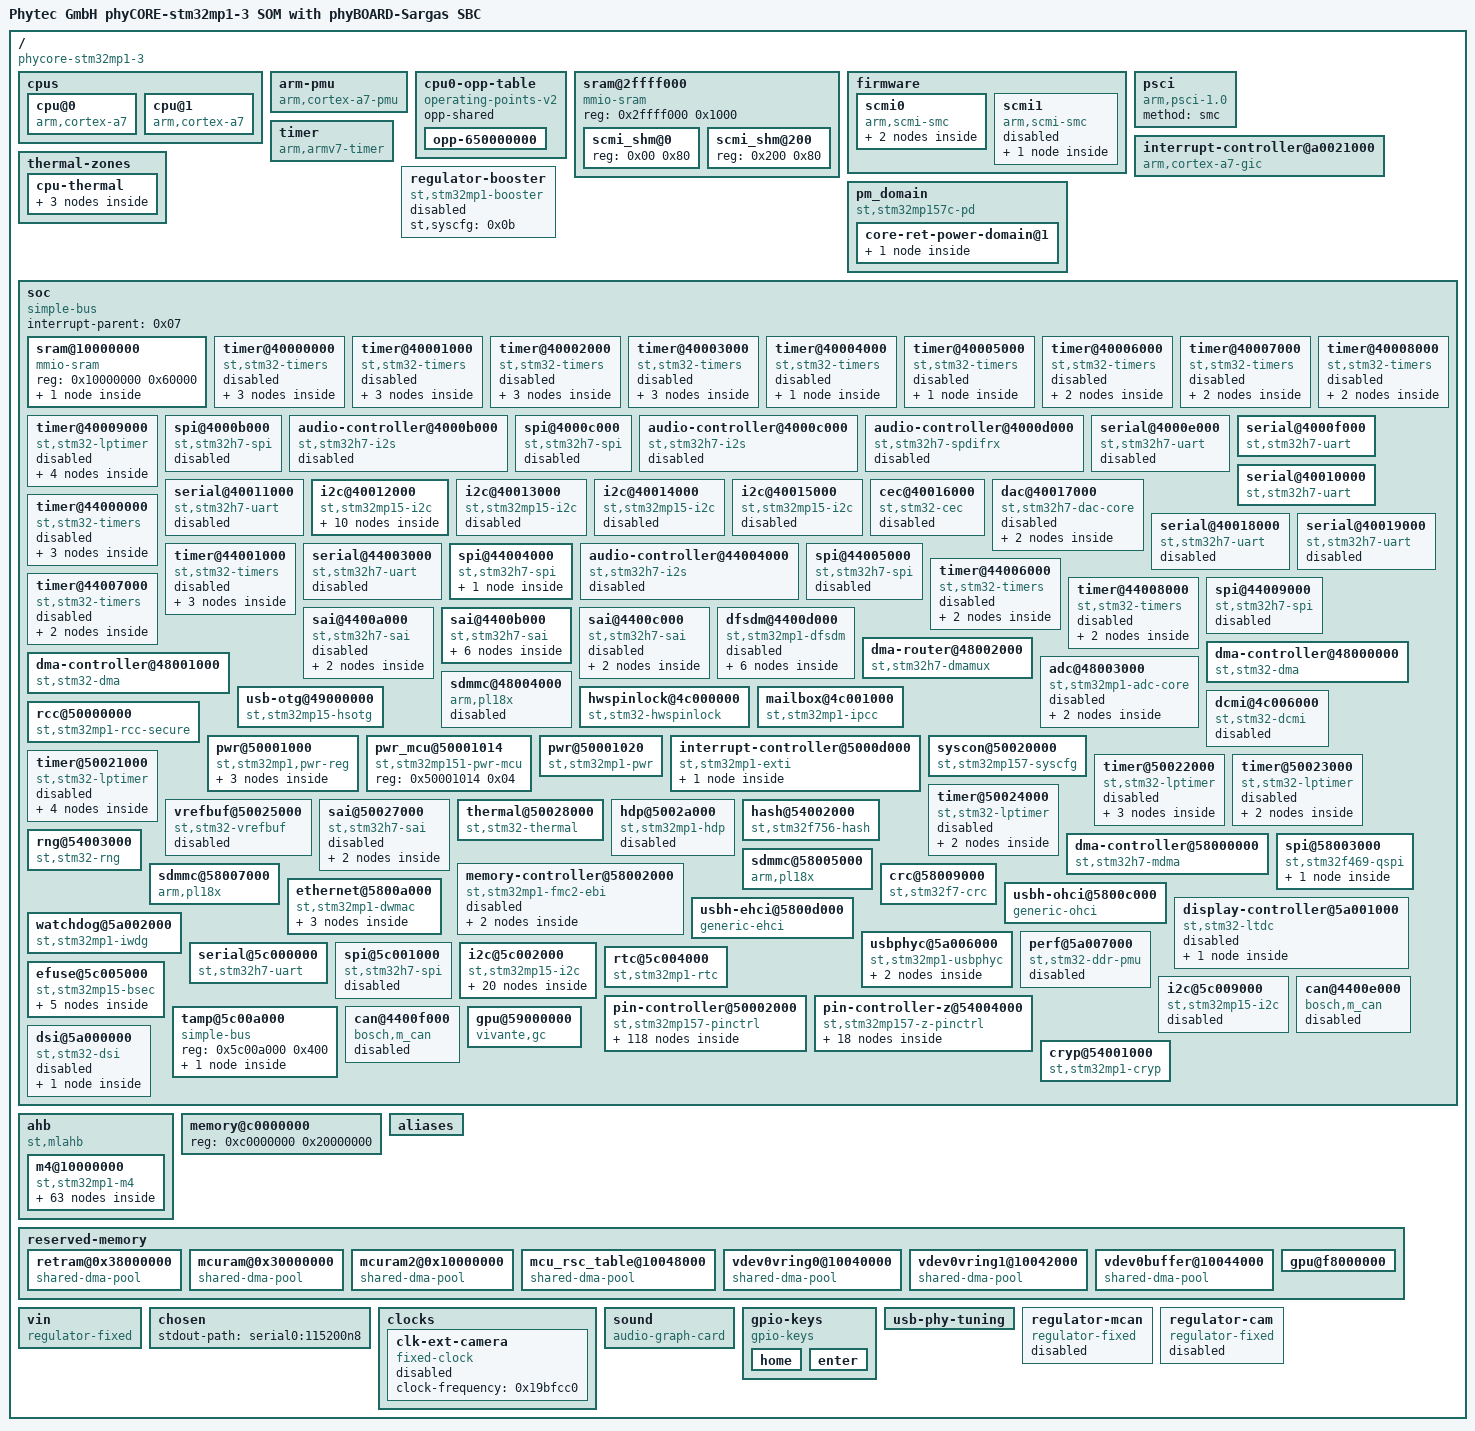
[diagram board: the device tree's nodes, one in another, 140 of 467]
/dts-v1/;

/ {
	#address-cells = <0x01>;
	#size-cells = <0x01>;
	model = "Phytec GmbH phyCORE-stm32mp1-3 SOM with phyBOARD-Sargas SBC";
	compatible = "phycore-stm32mp1-3\0phytec,stm32mp1-pcm068\0phytec,stm32mp1-pcm939\0st,stm32mp157";

	cpus {
		#address-cells = <0x01>;
		#size-cells = <0x00>;

		cpu@0 {
			compatible = "arm,cortex-a7";
			device_type = "cpu";
			reg = <0x00>;
			clocks = <0x01 0x07>;
			clock-names = "cpu";
			operating-points-v2 = <0x02>;
			nvmem-cells = <0x03>;
			nvmem-cell-names = "part_number";
			#cooling-cells = <0x02>;
			cpu-supply = <0x04>;
			phandle = <0x05>;
		};

		cpu@1 {
			compatible = "arm,cortex-a7";
			device_type = "cpu";
			reg = <0x01>;
			clocks = <0x01 0x07>;
			clock-names = "cpu";
			operating-points-v2 = <0x02>;
			cpu-supply = <0x04>;
			phandle = <0x06>;
		};
	};

	arm-pmu {
		compatible = "arm,cortex-a7-pmu";
		interrupts = <0x00 0xc8 0x04 0x00 0xc9 0x04>;
		interrupt-affinity = <0x05 0x06>;
		interrupt-parent = <0x07>;
	};

	cpu0-opp-table {
		compatible = "operating-points-v2";
		opp-shared;
		phandle = <0x02>;

		opp-650000000 {
			opp-hz = <0x00 0x26be3680>;
			opp-microvolt = <0x124f80>;
			opp-supported-hw = <0x01>;
		};
	};

	sram@2ffff000 {
		compatible = "mmio-sram";
		reg = <0x2ffff000 0x1000>;
		#address-cells = <0x01>;
		#size-cells = <0x01>;
		ranges = <0x00 0x2ffff000 0x1000>;
		phandle = <0x72>;

		scmi_shm@0 {
			reg = <0x00 0x80>;
			phandle = <0x08>;
		};

		scmi_shm@200 {
			reg = <0x200 0x80>;
			phandle = <0x09>;
		};
	};

	firmware {

		scmi0 {
			compatible = "arm,scmi-smc";
			#address-cells = <0x01>;
			#size-cells = <0x00>;
			arm,smc-id = <0x82002000>;
			shmem = <0x08>;
			phandle = <0x73>;

			protocol@14 {
				reg = <0x14>;
				#clock-cells = <0x01>;
				phandle = <0x01>;
			};

			protocol@16 {
				reg = <0x16>;
				#reset-cells = <0x01>;
				phandle = <0x38>;
			};
		};

		scmi1 {
			compatible = "arm,scmi-smc";
			#address-cells = <0x01>;
			#size-cells = <0x00>;
			arm,smc-id = <0x82002001>;
			shmem = <0x09>;
			status = "disabled";
			phandle = <0x74>;

			protocol@14 {
				reg = <0x14>;
				#clock-cells = <0x01>;
				phandle = <0x75>;
			};
		};
	};

	psci {
		compatible = "arm,psci-1.0";
		method = "smc";
	};

	interrupt-controller@a0021000 {
		compatible = "arm,cortex-a7-gic";
		#interrupt-cells = <0x03>;
		interrupt-controller;
		reg = <0xa0021000 0x1000 0xa0022000 0x2000>;
		phandle = <0x07>;
	};

	timer {
		compatible = "arm,armv7-timer";
		interrupts = <0x01 0x0d 0xf08 0x01 0x0e 0xf08 0x01 0x0b 0xf08 0x01 0x0a 0xf08>;
		interrupt-parent = <0x07>;
		always-on;
	};

	thermal-zones {

		cpu-thermal {
			polling-delay-passive = <0x00>;
			polling-delay = <0x00>;
			thermal-sensors = <0x0a>;
			phandle = <0x76>;

			trips {

				cpu-crit {
					temperature = <0x1d4c0>;
					hysteresis = <0x00>;
					type = "critical";
				};
			};

			cooling-maps {
			};
		};
	};

	regulator-booster {
		compatible = "st,stm32mp1-booster";
		st,syscfg = <0x0b>;
		status = "disabled";
		phandle = <0x77>;
	};

	pm_domain {
		#address-cells = <0x01>;
		#size-cells = <0x00>;
		compatible = "st,stm32mp157c-pd";

		core-ret-power-domain@1 {
			#address-cells = <0x01>;
			#size-cells = <0x00>;
			reg = <0x01>;
			#power-domain-cells = <0x00>;
			label = "CORE-RETENTION";
			phandle = <0x78>;

			core-power-domain@2 {
				reg = <0x02>;
				#power-domain-cells = <0x00>;
				label = "CORE";
				phandle = <0x0f>;
			};
		};
	};

	soc {
		compatible = "simple-bus";
		#address-cells = <0x01>;
		#size-cells = <0x01>;
		interrupt-parent = <0x07>;
		ranges;

		sram@10000000 {
			compatible = "mmio-sram";
			reg = <0x10000000 0x60000>;
			#address-cells = <0x01>;
			#size-cells = <0x01>;
			ranges = <0x00 0x10000000 0x60000>;
			phandle = <0x79>;

			dma_pool@0 {
				reg = <0x50000 0x10000>;
				pool;
				phandle = <0x28>;
			};
		};

		timer@40000000 {
			#address-cells = <0x01>;
			#size-cells = <0x00>;
			compatible = "st,stm32-timers";
			reg = <0x40000000 0x400>;
			clocks = <0x0c 0xc5>;
			clock-names = "int";
			dmas = <0x0d 0x12 0x400 0x80000001 0x0d 0x13 0x400 0x80000001 0x0d 0x14 0x400 0x80000001 0x0d 0x15 0x400 0x80000001 0x0d 0x16 0x400 0x80000001>;
			dma-names = "ch1\0ch2\0ch3\0ch4\0up";
			status = "disabled";
			phandle = <0x7a>;

			pwm {
				compatible = "st,stm32-pwm";
				#pwm-cells = <0x03>;
				status = "disabled";
			};

			timer@1 {
				compatible = "st,stm32h7-timer-trigger";
				reg = <0x01>;
				status = "disabled";
			};

			counter {
				compatible = "st,stm32-timer-counter";
				status = "disabled";
			};
		};

		timer@40001000 {
			#address-cells = <0x01>;
			#size-cells = <0x00>;
			compatible = "st,stm32-timers";
			reg = <0x40001000 0x400>;
			clocks = <0x0c 0xc6>;
			clock-names = "int";
			dmas = <0x0d 0x17 0x400 0x80000001 0x0d 0x18 0x400 0x80000001 0x0d 0x19 0x400 0x80000001 0x0d 0x1a 0x400 0x80000001 0x0d 0x1b 0x400 0x80000001 0x0d 0x1c 0x400 0x80000001>;
			dma-names = "ch1\0ch2\0ch3\0ch4\0up\0trig";
			status = "disabled";
			phandle = <0x7b>;

			pwm {
				compatible = "st,stm32-pwm";
				#pwm-cells = <0x03>;
				status = "disabled";
			};

			timer@2 {
				compatible = "st,stm32h7-timer-trigger";
				reg = <0x02>;
				status = "disabled";
			};

			counter {
				compatible = "st,stm32-timer-counter";
				status = "disabled";
			};
		};

		timer@40002000 {
			#address-cells = <0x01>;
			#size-cells = <0x00>;
			compatible = "st,stm32-timers";
			reg = <0x40002000 0x400>;
			clocks = <0x0c 0xc7>;
			clock-names = "int";
			dmas = <0x0d 0x1d 0x400 0x80000001 0x0d 0x1e 0x400 0x80000001 0x0d 0x1f 0x400 0x80000001 0x0d 0x20 0x400 0x80000001>;
			dma-names = "ch1\0ch2\0ch3\0ch4";
			status = "disabled";
			phandle = <0x7c>;

			pwm {
				compatible = "st,stm32-pwm";
				#pwm-cells = <0x03>;
				status = "disabled";
			};

			timer@3 {
				compatible = "st,stm32h7-timer-trigger";
				reg = <0x03>;
				status = "disabled";
			};

			counter {
				compatible = "st,stm32-timer-counter";
				status = "disabled";
			};
		};

		timer@40003000 {
			#address-cells = <0x01>;
			#size-cells = <0x00>;
			compatible = "st,stm32-timers";
			reg = <0x40003000 0x400>;
			clocks = <0x0c 0xc8>;
			clock-names = "int";
			dmas = <0x0d 0x37 0x400 0x80000001 0x0d 0x38 0x400 0x80000001 0x0d 0x39 0x400 0x80000001 0x0d 0x3a 0x400 0x80000001 0x0d 0x3b 0x400 0x80000001 0x0d 0x3c 0x400 0x80000001>;
			dma-names = "ch1\0ch2\0ch3\0ch4\0up\0trig";
			status = "disabled";
			phandle = <0x7d>;

			pwm {
				compatible = "st,stm32-pwm";
				#pwm-cells = <0x03>;
				status = "disabled";
			};

			timer@4 {
				compatible = "st,stm32h7-timer-trigger";
				reg = <0x04>;
				status = "disabled";
			};

			counter {
				compatible = "st,stm32-timer-counter";
				status = "disabled";
			};
		};

		timer@40004000 {
			#address-cells = <0x01>;
			#size-cells = <0x00>;
			compatible = "st,stm32-timers";
			reg = <0x40004000 0x400>;
			clocks = <0x0c 0xc9>;
			clock-names = "int";
			dmas = <0x0d 0x45 0x400 0x80000001>;
			dma-names = "up";
			status = "disabled";
			phandle = <0x7e>;

			timer@5 {
				compatible = "st,stm32h7-timer-trigger";
				reg = <0x05>;
				status = "disabled";
			};
		};

		timer@40005000 {
			#address-cells = <0x01>;
			#size-cells = <0x00>;
			compatible = "st,stm32-timers";
			reg = <0x40005000 0x400>;
			clocks = <0x0c 0xca>;
			clock-names = "int";
			dmas = <0x0d 0x46 0x400 0x80000001>;
			dma-names = "up";
			status = "disabled";
			phandle = <0x7f>;

			timer@6 {
				compatible = "st,stm32h7-timer-trigger";
				reg = <0x06>;
				status = "disabled";
			};
		};

		timer@40006000 {
			#address-cells = <0x01>;
			#size-cells = <0x00>;
			compatible = "st,stm32-timers";
			reg = <0x40006000 0x400>;
			clocks = <0x0c 0xcb>;
			clock-names = "int";
			status = "disabled";
			phandle = <0x80>;

			pwm {
				compatible = "st,stm32-pwm";
				#pwm-cells = <0x03>;
				status = "disabled";
			};

			timer@11 {
				compatible = "st,stm32h7-timer-trigger";
				reg = <0x0b>;
				status = "disabled";
			};
		};

		timer@40007000 {
			#address-cells = <0x01>;
			#size-cells = <0x00>;
			compatible = "st,stm32-timers";
			reg = <0x40007000 0x400>;
			clocks = <0x0c 0xcc>;
			clock-names = "int";
			status = "disabled";
			phandle = <0x81>;

			pwm {
				compatible = "st,stm32-pwm";
				#pwm-cells = <0x03>;
				status = "disabled";
			};

			timer@12 {
				compatible = "st,stm32h7-timer-trigger";
				reg = <0x0c>;
				status = "disabled";
			};
		};

		timer@40008000 {
			#address-cells = <0x01>;
			#size-cells = <0x00>;
			compatible = "st,stm32-timers";
			reg = <0x40008000 0x400>;
			clocks = <0x0c 0xcd>;
			clock-names = "int";
			status = "disabled";
			phandle = <0x82>;

			pwm {
				compatible = "st,stm32-pwm";
				#pwm-cells = <0x03>;
				status = "disabled";
			};

			timer@13 {
				compatible = "st,stm32h7-timer-trigger";
				reg = <0x0d>;
				status = "disabled";
			};
		};

		timer@40009000 {
			#address-cells = <0x01>;
			#size-cells = <0x00>;
			compatible = "st,stm32-lptimer";
			reg = <0x40009000 0x400>;
			interrupts-extended = <0x0e 0x2f 0x04>;
			clocks = <0x0c 0x8f>;
			clock-names = "mux";
			power-domains = <0x0f>;
			wakeup-source;
			status = "disabled";
			phandle = <0x83>;

			pwm {
				compatible = "st,stm32-pwm-lp";
				#pwm-cells = <0x03>;
				status = "disabled";
			};

			trigger@0 {
				compatible = "st,stm32-lptimer-trigger";
				reg = <0x00>;
				status = "disabled";
			};

			counter {
				compatible = "st,stm32-lptimer-counter";
				status = "disabled";
			};

			timer {
				compatible = "st,stm32-lptimer-timer";
				status = "disabled";
			};
		};

		spi@4000b000 {
			#address-cells = <0x01>;
			#size-cells = <0x00>;
			compatible = "st,stm32h7-spi";
			reg = <0x4000b000 0x400>;
			interrupts = <0x00 0x24 0x04>;
			clocks = <0x0c 0x83>;
			resets = <0x0c 0x4c0b>;
			dmas = <0x0d 0x27 0x400 0x01 0x0d 0x28 0x400 0x01>;
			dma-names = "rx\0tx";
			power-domains = <0x0f>;
			status = "disabled";
			phandle = <0x84>;
		};

		audio-controller@4000b000 {
			compatible = "st,stm32h7-i2s";
			#sound-dai-cells = <0x00>;
			reg = <0x4000b000 0x400>;
			interrupts = <0x00 0x24 0x04>;
			dmas = <0x0d 0x27 0x400 0x01 0x0d 0x28 0x400 0x01>;
			dma-names = "rx\0tx";
			status = "disabled";
			phandle = <0x85>;
		};

		spi@4000c000 {
			#address-cells = <0x01>;
			#size-cells = <0x00>;
			compatible = "st,stm32h7-spi";
			reg = <0x4000c000 0x400>;
			interrupts = <0x00 0x33 0x04>;
			clocks = <0x0c 0x84>;
			resets = <0x0c 0x4c0c>;
			dmas = <0x0d 0x3d 0x400 0x01 0x0d 0x3e 0x400 0x01>;
			dma-names = "rx\0tx";
			power-domains = <0x0f>;
			status = "disabled";
			phandle = <0x86>;
		};

		audio-controller@4000c000 {
			compatible = "st,stm32h7-i2s";
			#sound-dai-cells = <0x00>;
			reg = <0x4000c000 0x400>;
			interrupts = <0x00 0x33 0x04>;
			dmas = <0x0d 0x3d 0x400 0x01 0x0d 0x3e 0x400 0x01>;
			dma-names = "rx\0tx";
			status = "disabled";
			phandle = <0x87>;
		};

		audio-controller@4000d000 {
			compatible = "st,stm32h7-spdifrx";
			#sound-dai-cells = <0x00>;
			reg = <0x4000d000 0x400>;
			clocks = <0x0c 0x81>;
			clock-names = "kclk";
			interrupts = <0x00 0x61 0x04>;
			dmas = <0x0d 0x5d 0x400 0x01 0x0d 0x5e 0x400 0x01>;
			dma-names = "rx\0rx-ctrl";
			status = "disabled";
			phandle = <0x88>;
		};

		serial@4000e000 {
			compatible = "st,stm32h7-uart";
			reg = <0x4000e000 0x400>;
			interrupts-extended = <0x0e 0x1b 0x04>;
			clocks = <0x0c 0x95>;
			wakeup-source;
			power-domains = <0x0f>;
			dmas = <0x0d 0x2b 0x400 0x15 0x0d 0x2c 0x400 0x11>;
			dma-names = "rx\0tx";
			status = "disabled";
			phandle = <0x89>;
		};

		serial@4000f000 {
			compatible = "st,stm32h7-uart";
			reg = <0x4000f000 0x400>;
			interrupts-extended = <0x0e 0x1c 0x04>;
			clocks = <0x0c 0x96>;
			wakeup-source;
			power-domains = <0x0f>;
			dmas = <0x0d 0x2d 0x400 0x15 0x0d 0x2e 0x400 0x11>;
			dma-names = "rx\0tx";
			status = "okay";
			pinctrl-names = "default\0sleep\0idle";
			pinctrl-0 = <0x10>;
			pinctrl-1 = <0x11>;
			pinctrl-2 = <0x12>;
			phandle = <0x8a>;
		};

		serial@40010000 {
			compatible = "st,stm32h7-uart";
			reg = <0x40010000 0x400>;
			interrupts-extended = <0x0e 0x1e 0x04>;
			clocks = <0x0c 0x97>;
			wakeup-source;
			power-domains = <0x0f>;
			status = "okay";
			pinctrl-names = "default\0sleep\0idle";
			pinctrl-0 = <0x13>;
			pinctrl-1 = <0x14>;
			pinctrl-2 = <0x15>;
			pinctrl-3 = <0x13>;
			phandle = <0x8b>;
		};

		serial@40011000 {
			compatible = "st,stm32h7-uart";
			reg = <0x40011000 0x400>;
			interrupts-extended = <0x0e 0x1f 0x04>;
			clocks = <0x0c 0x98>;
			wakeup-source;
			power-domains = <0x0f>;
			dmas = <0x0d 0x41 0x400 0x15 0x0d 0x42 0x400 0x11>;
			dma-names = "rx\0tx";
			status = "disabled";
			phandle = <0x8c>;
		};

		i2c@40012000 {
			compatible = "st,stm32mp15-i2c";
			reg = <0x40012000 0x400>;
			interrupt-names = "event\0error";
			interrupts-extended = <0x0e 0x15 0x04 0x07 0x00 0x20 0x04>;
			clocks = <0x0c 0x89>;
			resets = <0x0c 0x4c15>;
			#address-cells = <0x01>;
			#size-cells = <0x00>;
			power-domains = <0x0f>;
			st,syscfg-fmp = <0x0b 0x04 0x01>;
			wakeup-source;
			i2c-analog-filter;
			status = "okay";
			pinctrl-names = "default\0sleep";
			pinctrl-0 = <0x16>;
			pinctrl-1 = <0x17>;
			i2c-scl-rising-time-ns = <0x64>;
			i2c-scl-falling-time-ns = <0x07>;
			phandle = <0x8d>;

			tlv320@18 {
				compatible = "ti,tlv320aic3007";
				#sound-dai-cells = <0x00>;
				reg = <0x18>;
				status = "okay";
				ai3x-micbias-vg = <0x02>;
				AVDD-supply = <0x18>;
				IOVDD-supply = <0x18>;
				DRVDD-supply = <0x18>;
				DVDD-supply = <0x19>;
				clocks = <0x1a>;
				clock-names = "MCLK";
				phandle = <0x8e>;

				port {
					#address-cells = <0x01>;
					#size-cells = <0x00>;
					phandle = <0x8f>;

					endpoint@0 {
						reg = <0x00>;
						remote-endpoint = <0x1b>;
						frame-master;
						bitclock-master;
						phandle = <0x26>;
					};

					endpoint@1 {
						reg = <0x01>;
						remote-endpoint = <0x1c>;
						frame-master;
						bitclock-master;
						phandle = <0x25>;
					};
				};
			};

			stmpe811@44 {
				compatible = "st,stmpe811";
				reg = <0x44>;
				interrupts = <0x03 0x02>;
				interrupt-parent = <0x1d>;
				vio-supply = <0x18>;
				vcc-supply = <0x18>;
				status = "disabled";
				phandle = <0x90>;

				stmpe_touchscreen {
					compatible = "st,stmpe-ts";
					st,sample-time = <0x04>;
					st,mod-12b = <0x01>;
					st,ref-sel = <0x00>;
					st,adc-freq = <0x01>;
					st,ave-ctrl = <0x01>;
					st,touch-det-delay = <0x02>;
					st,settling = <0x02>;
					st,fraction-z = <0x07>;
					st,i-drive = <0x01>;
				};
			};

			pca9533@62 {
				compatible = "nxp,pca9533";
				reg = <0x62>;
				status = "okay";
				phandle = <0x91>;

				red-power {
					label = "pca:red:power";
					type = <0x01>;
				};

				green-power {
					label = "pca:green:power";
					type = <0x01>;
				};

				blue-power {
					type = <0x01>;
					linux,default-trigger = "heartbeat";
				};
			};
		};

		i2c@40013000 {
			compatible = "st,stm32mp15-i2c";
			reg = <0x40013000 0x400>;
			interrupt-names = "event\0error";
			interrupts-extended = <0x0e 0x16 0x04 0x07 0x00 0x22 0x04>;
			clocks = <0x0c 0x8a>;
			resets = <0x0c 0x4c16>;
			#address-cells = <0x01>;
			#size-cells = <0x00>;
			dmas = <0x0d 0x23 0x400 0x80000001 0x0d 0x24 0x400 0x80000001>;
			dma-names = "rx\0tx";
			power-domains = <0x0f>;
			st,syscfg-fmp = <0x0b 0x04 0x02>;
			wakeup-source;
			i2c-analog-filter;
			status = "disabled";
			phandle = <0x92>;
		};

		i2c@40014000 {
			compatible = "st,stm32mp15-i2c";
			reg = <0x40014000 0x400>;
			interrupt-names = "event\0error";
			interrupts-extended = <0x0e 0x17 0x04 0x07 0x00 0x49 0x04>;
			clocks = <0x0c 0x8b>;
			resets = <0x0c 0x4c17>;
			#address-cells = <0x01>;
			#size-cells = <0x00>;
			dmas = <0x0d 0x49 0x400 0x80000001 0x0d 0x4a 0x400 0x80000001>;
			dma-names = "rx\0tx";
			power-domains = <0x0f>;
			st,syscfg-fmp = <0x0b 0x04 0x04>;
			wakeup-source;
			i2c-analog-filter;
			status = "disabled";
			phandle = <0x93>;
		};

		i2c@40015000 {
			compatible = "st,stm32mp15-i2c";
			reg = <0x40015000 0x400>;
			interrupt-names = "event\0error";
			interrupts-extended = <0x0e 0x19 0x04 0x07 0x00 0x6c 0x04>;
			clocks = <0x0c 0x8d>;
			resets = <0x0c 0x4c18>;
			#address-cells = <0x01>;
			#size-cells = <0x00>;
			dmas = <0x0d 0x73 0x400 0x80000001 0x0d 0x74 0x400 0x80000001>;
			dma-names = "rx\0tx";
			power-domains = <0x0f>;
			st,syscfg-fmp = <0x0b 0x04 0x10>;
			wakeup-source;
			i2c-analog-filter;
			status = "disabled";
			phandle = <0x94>;
		};

		cec@40016000 {
			compatible = "st,stm32-cec";
			reg = <0x40016000 0x400>;
			interrupts = <0x00 0x5e 0x04>;
			clocks = <0x0c 0x88 0x0c 0x1d>;
			clock-names = "cec\0hdmi-cec";
			status = "disabled";
			phandle = <0x95>;
		};

		dac@40017000 {
			compatible = "st,stm32h7-dac-core";
			reg = <0x40017000 0x400>;
			clocks = <0x0c 0x1e>;
			clock-names = "pclk";
			#address-cells = <0x01>;
			#size-cells = <0x00>;
			status = "disabled";
			phandle = <0x96>;

			dac@1 {
				compatible = "st,stm32-dac";
				#io-channel-cells = <0x01>;
				reg = <0x01>;
				status = "disabled";
				phandle = <0x97>;
			};

			dac@2 {
				compatible = "st,stm32-dac";
				#io-channel-cells = <0x01>;
				reg = <0x02>;
				status = "disabled";
				phandle = <0x98>;
			};
		};

		serial@40018000 {
			compatible = "st,stm32h7-uart";
			reg = <0x40018000 0x400>;
			interrupts-extended = <0x0e 0x20 0x04>;
			clocks = <0x0c 0x9a>;
			wakeup-source;
			power-domains = <0x0f>;
			dmas = <0x0d 0x4f 0x400 0x15 0x0d 0x50 0x400 0x11>;
			dma-names = "rx\0tx";
			status = "disabled";
			phandle = <0x99>;
		};

		serial@40019000 {
			compatible = "st,stm32h7-uart";
			reg = <0x40019000 0x400>;
			interrupts-extended = <0x0e 0x21 0x04>;
			clocks = <0x0c 0x9b>;
			wakeup-source;
			power-domains = <0x0f>;
			dmas = <0x0d 0x51 0x400 0x15 0x0d 0x52 0x400 0x11>;
			dma-names = "rx\0tx";
			status = "disabled";
			phandle = <0x9a>;
		};

		timer@44000000 {
			#address-cells = <0x01>;
			#size-cells = <0x00>;
			compatible = "st,stm32-timers";
			reg = <0x44000000 0x400>;
			clocks = <0x0c 0xce>;
			clock-names = "int";
			dmas = <0x0d 0x0b 0x400 0x80000001 0x0d 0x0c 0x400 0x80000001 0x0d 0x0d 0x400 0x80000001 0x0d 0x0e 0x400 0x80000001 0x0d 0x0f 0x400 0x80000001 0x0d 0x10 0x400 0x80000001 0x0d 0x11 0x400 0x80000001>;
			dma-names = "ch1\0ch2\0ch3\0ch4\0up\0trig\0com";
			status = "disabled";
			phandle = <0x9b>;

			pwm {
				compatible = "st,stm32-pwm";
				#pwm-cells = <0x03>;
				status = "disabled";
			};

			timer@0 {
				compatible = "st,stm32h7-timer-trigger";
				reg = <0x00>;
				status = "disabled";
			};

			counter {
				compatible = "st,stm32-timer-counter";
				status = "disabled";
			};
		};

		timer@44001000 {
			#address-cells = <0x01>;
			#size-cells = <0x00>;
			compatible = "st,stm32-timers";
			reg = <0x44001000 0x400>;
			clocks = <0x0c 0xcf>;
			clock-names = "int";
			dmas = <0x0d 0x2f 0x400 0x80000001 0x0d 0x30 0x400 0x80000001 0x0d 0x31 0x400 0x80000001 0x0d 0x32 0x400 0x80000001 0x0d 0x33 0x400 0x80000001 0x0d 0x34 0x400 0x80000001 0x0d 0x35 0x400 0x80000001>;
			dma-names = "ch1\0ch2\0ch3\0ch4\0up\0trig\0com";
			status = "disabled";
			phandle = <0x9c>;

			pwm {
				compatible = "st,stm32-pwm";
				#pwm-cells = <0x03>;
				status = "disabled";
			};

			timer@7 {
				compatible = "st,stm32h7-timer-trigger";
				reg = <0x07>;
				status = "disabled";
			};

			counter {
				compatible = "st,stm32-timer-counter";
				status = "disabled";
			};
		};

		serial@44003000 {
			compatible = "st,stm32h7-uart";
			reg = <0x44003000 0x400>;
			interrupts-extended = <0x0e 0x1d 0x04>;
			clocks = <0x0c 0x99>;
			wakeup-source;
			power-domains = <0x0f>;
			dmas = <0x0d 0x47 0x400 0x15 0x0d 0x48 0x400 0x11>;
			dma-names = "rx\0tx";
			status = "disabled";
			phandle = <0x9d>;
		};

		spi@44004000 {
			#address-cells = <0x01>;
			#size-cells = <0x00>;
			compatible = "st,stm32h7-spi";
			reg = <0x44004000 0x400>;
			interrupts = <0x00 0x23 0x04>;
			clocks = <0x0c 0x82>;
			resets = <0x0c 0x4c48>;
			dmas = <0x0d 0x25 0x400 0x01 0x0d 0x26 0x400 0x01>;
			dma-names = "rx\0tx";
			power-domains = <0x0f>;
			status = "okay";
			pinctrl-names = "default\0sleep";
			pinctrl-0 = <0x1e>;
			pinctrl-1 = <0x1f>;
			cs-gpios = <0x20 0x03 0x00>;
			phandle = <0x9e>;

			spi@0 {
				compatible = "linux,spidev";
				spi-max-frequency = <0x989680>;
				reg = <0x00>;
			};
		};

		audio-controller@44004000 {
			compatible = "st,stm32h7-i2s";
			#sound-dai-cells = <0x00>;
			reg = <0x44004000 0x400>;
			interrupts = <0x00 0x23 0x04>;
			dmas = <0x0d 0x25 0x400 0x01 0x0d 0x26 0x400 0x01>;
			dma-names = "rx\0tx";
			status = "disabled";
			phandle = <0x9f>;
		};

		spi@44005000 {
			#address-cells = <0x01>;
			#size-cells = <0x00>;
			compatible = "st,stm32h7-spi";
			reg = <0x44005000 0x400>;
			interrupts = <0x00 0x54 0x04>;
			clocks = <0x0c 0x85>;
			resets = <0x0c 0x4c49>;
			dmas = <0x0d 0x53 0x400 0x01 0x0d 0x54 0x400 0x01>;
			dma-names = "rx\0tx";
			power-domains = <0x0f>;
			status = "disabled";
			phandle = <0xa0>;
		};

		timer@44006000 {
			#address-cells = <0x01>;
			#size-cells = <0x00>;
			compatible = "st,stm32-timers";
			reg = <0x44006000 0x400>;
			clocks = <0x0c 0xd0>;
			clock-names = "int";
			dmas = <0x0d 0x69 0x400 0x80000001 0x0d 0x6a 0x400 0x80000001 0x0d 0x6b 0x400 0x80000001 0x0d 0x6c 0x400 0x80000001>;
			dma-names = "ch1\0up\0trig\0com";
			status = "disabled";
			phandle = <0xa1>;

			pwm {
				compatible = "st,stm32-pwm";
				#pwm-cells = <0x03>;
				status = "disabled";
			};

			timer@14 {
				compatible = "st,stm32h7-timer-trigger";
				reg = <0x0e>;
				status = "disabled";
			};
		};

		timer@44007000 {
			#address-cells = <0x01>;
			#size-cells = <0x00>;
			compatible = "st,stm32-timers";
			reg = <0x44007000 0x400>;
			clocks = <0x0c 0xd1>;
			clock-names = "int";
			dmas = <0x0d 0x6d 0x400 0x80000001 0x0d 0x6e 0x400 0x80000001>;
			dma-names = "ch1\0up";
			status = "disabled";
			phandle = <0xa2>;

			pwm {
				compatible = "st,stm32-pwm";
				#pwm-cells = <0x03>;
				status = "disabled";
			};

			timer@15 {
				compatible = "st,stm32h7-timer-trigger";
				reg = <0x0f>;
				status = "disabled";
			};
		};

		timer@44008000 {
			#address-cells = <0x01>;
			#size-cells = <0x00>;
			compatible = "st,stm32-timers";
			reg = <0x44008000 0x400>;
			clocks = <0x0c 0xd2>;
			clock-names = "int";
			dmas = <0x0d 0x6f 0x400 0x80000001 0x0d 0x70 0x400 0x80000001>;
			dma-names = "ch1\0up";
			status = "disabled";
			phandle = <0xa3>;

			pwm {
				compatible = "st,stm32-pwm";
				#pwm-cells = <0x03>;
				status = "disabled";
			};

			timer@16 {
				compatible = "st,stm32h7-timer-trigger";
				reg = <0x10>;
				status = "disabled";
			};
		};

		spi@44009000 {
			#address-cells = <0x01>;
			#size-cells = <0x00>;
			compatible = "st,stm32h7-spi";
			reg = <0x44009000 0x400>;
			interrupts = <0x00 0x55 0x04>;
			clocks = <0x0c 0x86>;
			resets = <0x0c 0x4c4a>;
			dmas = <0x0d 0x55 0x400 0x01 0x0d 0x56 0x400 0x01>;
			dma-names = "rx\0tx";
			power-domains = <0x0f>;
			status = "disabled";
			phandle = <0xa4>;
		};

		sai@4400a000 {
			compatible = "st,stm32h7-sai";
			#address-cells = <0x01>;
			#size-cells = <0x01>;
			ranges = <0x00 0x4400a000 0x400>;
			reg = <0x4400a000 0x04 0x4400a3f0 0x10>;
			interrupts = <0x00 0x57 0x04>;
			resets = <0x0c 0x4c50>;
			status = "disabled";
			phandle = <0xa5>;

			audio-controller@4400a004 {
				#sound-dai-cells = <0x00>;
				compatible = "st,stm32-sai-sub-a";
				reg = <0x04 0x20>;
				clocks = <0x0c 0x9e>;
				clock-names = "sai_ck";
				dmas = <0x0d 0x57 0x400 0x01>;
				status = "disabled";
				phandle = <0xa6>;
			};

			audio-controller@4400a024 {
				#sound-dai-cells = <0x00>;
				compatible = "st,stm32-sai-sub-b";
				reg = <0x24 0x20>;
				clocks = <0x0c 0x9e>;
				clock-names = "sai_ck";
				dmas = <0x0d 0x58 0x400 0x01>;
				status = "disabled";
				phandle = <0xa7>;
			};
		};

		sai@4400b000 {
			compatible = "st,stm32h7-sai";
			#address-cells = <0x01>;
			#size-cells = <0x01>;
			ranges = <0x00 0x4400b000 0x400>;
			reg = <0x4400b000 0x04 0x4400b3f0 0x10>;
			interrupts = <0x00 0x5b 0x04>;
			resets = <0x0c 0x4c51>;
			status = "okay";
			clocks = <0x0c 0x2a 0x0c 0xbb 0x0c 0xbc>;
			clock-names = "pclk\0x8k\0x11k";
			pinctrl-names = "default\0sleep";
			pinctrl-0 = <0x21 0x22>;
			pinctrl-1 = <0x23 0x24>;
			phandle = <0xa8>;

			audio-controller@4400b004 {
				#sound-dai-cells = <0x00>;
				compatible = "st,stm32-sai-sub-a";
				reg = <0x04 0x20>;
				clocks = <0x0c 0x9f 0x1a>;
				clock-names = "sai_ck\0MCLK";
				dmas = <0x0d 0x59 0x400 0x01>;
				status = "okay";
				dma-names = "rx";
				st,sync = <0x1a 0x02>;
				phandle = <0xa9>;

				port {
					phandle = <0x71>;

					endpoint {
						remote-endpoint = <0x25>;
						format = "i2s";
						mclk-fs = <0x100>;
						dai-tdm-slot-num = <0x02>;
						dai-tdm-slot-width = <0x10>;
						phandle = <0x1c>;
					};
				};
			};

			audio-controller@4400b024 {
				#sound-dai-cells = <0x00>;
				compatible = "st,stm32-sai-sub-b";
				reg = <0x24 0x20>;
				clocks = <0x0c 0x9f>;
				clock-names = "sai_ck";
				dmas = <0x0d 0x5a 0x400 0x01>;
				status = "okay";
				#clock-cells = <0x00>;
				dma-names = "tx";
				phandle = <0x1a>;

				port {
					phandle = <0x70>;

					endpoint {
						remote-endpoint = <0x26>;
						format = "i2s";
						mclk-fs = <0x100>;
						dai-tdm-slot-num = <0x02>;
						dai-tdm-slot-width = <0x10>;
						phandle = <0x1b>;
					};
				};
			};
		};

		sai@4400c000 {
			compatible = "st,stm32h7-sai";
			#address-cells = <0x01>;
			#size-cells = <0x01>;
			ranges = <0x00 0x4400c000 0x400>;
			reg = <0x4400c000 0x04 0x4400c3f0 0x10>;
			interrupts = <0x00 0x72 0x04>;
			resets = <0x0c 0x4c52>;
			status = "disabled";
			phandle = <0xaa>;

			audio-controller@4400c004 {
				#sound-dai-cells = <0x00>;
				compatible = "st,stm32-sai-sub-a";
				reg = <0x04 0x20>;
				clocks = <0x0c 0xa0>;
				clock-names = "sai_ck";
				dmas = <0x0d 0x71 0x400 0x01>;
				status = "disabled";
				phandle = <0xab>;
			};

			audio-controller@4400c024 {
				#sound-dai-cells = <0x00>;
				compatible = "st,stm32-sai-sub-b";
				reg = <0x24 0x20>;
				clocks = <0x0c 0xa0>;
				clock-names = "sai_ck";
				dmas = <0x0d 0x72 0x400 0x01>;
				status = "disabled";
				phandle = <0xac>;
			};
		};

		dfsdm@4400d000 {
			compatible = "st,stm32mp1-dfsdm";
			reg = <0x4400d000 0x800>;
			clocks = <0x0c 0x9c>;
			clock-names = "dfsdm";
			#address-cells = <0x01>;
			#size-cells = <0x00>;
			status = "disabled";
			phandle = <0xad>;

			filter@0 {
				compatible = "st,stm32-dfsdm-adc";
				#io-channel-cells = <0x01>;
				reg = <0x00>;
				interrupts = <0x00 0x6e 0x04>;
				dmas = <0x0d 0x65 0x400 0x01>;
				dma-names = "rx";
				status = "disabled";
				phandle = <0xae>;
			};

			filter@1 {
				compatible = "st,stm32-dfsdm-adc";
				#io-channel-cells = <0x01>;
				reg = <0x01>;
				interrupts = <0x00 0x6f 0x04>;
				dmas = <0x0d 0x66 0x400 0x01>;
				dma-names = "rx";
				status = "disabled";
				phandle = <0xaf>;
			};

			filter@2 {
				compatible = "st,stm32-dfsdm-adc";
				#io-channel-cells = <0x01>;
				reg = <0x02>;
				interrupts = <0x00 0x70 0x04>;
				dmas = <0x0d 0x67 0x400 0x01>;
				dma-names = "rx";
				status = "disabled";
				phandle = <0xb0>;
			};

			filter@3 {
				compatible = "st,stm32-dfsdm-adc";
				#io-channel-cells = <0x01>;
				reg = <0x03>;
				interrupts = <0x00 0x71 0x04>;
				dmas = <0x0d 0x68 0x400 0x01>;
				dma-names = "rx";
				status = "disabled";
				phandle = <0xb1>;
			};

			filter@4 {
				compatible = "st,stm32-dfsdm-adc";
				#io-channel-cells = <0x01>;
				reg = <0x04>;
				interrupts = <0x00 0x73 0x04>;
				dmas = <0x0d 0x5b 0x400 0x01>;
				dma-names = "rx";
				status = "disabled";
				phandle = <0xb2>;
			};

			filter@5 {
				compatible = "st,stm32-dfsdm-adc";
				#io-channel-cells = <0x01>;
				reg = <0x05>;
				interrupts = <0x00 0x7e 0x04>;
				dmas = <0x0d 0x5c 0x400 0x01>;
				dma-names = "rx";
				status = "disabled";
				phandle = <0xb3>;
			};
		};

		dma-controller@48000000 {
			compatible = "st,stm32-dma";
			reg = <0x48000000 0x400>;
			interrupts = <0x00 0x0b 0x04 0x00 0x0c 0x04 0x00 0x0d 0x04 0x00 0x0e 0x04 0x00 0x0f 0x04 0x00 0x10 0x04 0x00 0x11 0x04 0x00 0x2f 0x04>;
			clocks = <0x0c 0x47>;
			resets = <0x0c 0x4cc0>;
			#dma-cells = <0x04>;
			st,mem2mem;
			dma-requests = <0x08>;
			dmas = <0x27 0x00 0x03 0x1200000a 0x48000008 0x20 0x01 0x27 0x01 0x03 0x1200000a 0x48000008 0x800 0x01 0x27 0x02 0x03 0x1200000a 0x48000008 0x200000 0x01 0x27 0x03 0x03 0x1200000a 0x48000008 0x8000000 0x01 0x27 0x04 0x03 0x1200000a 0x4800000c 0x20 0x01 0x27 0x05 0x03 0x1200000a 0x4800000c 0x800 0x01 0x27 0x06 0x03 0x1200000a 0x4800000c 0x200000 0x01 0x27 0x07 0x03 0x1200000a 0x4800000c 0x8000000 0x01>;
			dma-names = "ch0\0ch1\0ch2\0ch3\0ch4\0ch5\0ch6\0ch7";
			sram = <0x28>;
			phandle = <0x29>;
		};

		dma-controller@48001000 {
			compatible = "st,stm32-dma";
			reg = <0x48001000 0x400>;
			interrupts = <0x00 0x38 0x04 0x00 0x39 0x04 0x00 0x3a 0x04 0x00 0x3b 0x04 0x00 0x3c 0x04 0x00 0x44 0x04 0x00 0x45 0x04 0x00 0x46 0x04>;
			clocks = <0x0c 0x48>;
			resets = <0x0c 0x4cc1>;
			#dma-cells = <0x04>;
			st,mem2mem;
			dma-requests = <0x08>;
			dmas = <0x27 0x08 0x03 0x1200000a 0x48001008 0x20 0x01 0x27 0x09 0x03 0x1200000a 0x48001008 0x800 0x01 0x27 0x0a 0x03 0x1200000a 0x48001008 0x200000 0x01 0x27 0x0b 0x03 0x1200000a 0x48001008 0x8000000 0x01 0x27 0x0c 0x03 0x1200000a 0x4800100c 0x20 0x01 0x27 0x0d 0x03 0x1200000a 0x4800100c 0x800 0x01 0x27 0x0e 0x03 0x1200000a 0x4800100c 0x200000 0x01 0x27 0x0f 0x03 0x1200000a 0x4800100c 0x8000000 0x01>;
			dma-names = "ch0\0ch1\0ch2\0ch3\0ch4\0ch5\0ch6\0ch7";
			sram = <0x28>;
			phandle = <0x2a>;
		};

		dma-router@48002000 {
			compatible = "st,stm32h7-dmamux";
			reg = <0x48002000 0x40>;
			#dma-cells = <0x03>;
			dma-requests = <0x80>;
			dma-masters = <0x29 0x2a>;
			dma-channels = <0x10>;
			clocks = <0x0c 0x49>;
			resets = <0x0c 0x4cc2>;
			phandle = <0x0d>;
		};

		adc@48003000 {
			compatible = "st,stm32mp1-adc-core";
			reg = <0x48003000 0x400>;
			interrupts = <0x00 0x12 0x04 0x00 0x5a 0x04>;
			clocks = <0x0c 0x4a 0x0c 0xa2>;
			clock-names = "bus\0adc";
			interrupt-controller;
			st,syscfg = <0x0b>;
			#interrupt-cells = <0x01>;
			#address-cells = <0x01>;
			#size-cells = <0x00>;
			status = "disabled";
			phandle = <0x2b>;

			adc@0 {
				compatible = "st,stm32mp1-adc";
				#io-channel-cells = <0x01>;
				reg = <0x00>;
				interrupt-parent = <0x2b>;
				interrupts = <0x00>;
				dmas = <0x0d 0x09 0x400 0x80000001>;
				dma-names = "rx";
				status = "disabled";
				phandle = <0xb4>;
			};

			adc@100 {
				compatible = "st,stm32mp1-adc";
				#io-channel-cells = <0x01>;
				reg = <0x100>;
				interrupt-parent = <0x2b>;
				interrupts = <0x01>;
				dmas = <0x0d 0x0a 0x400 0x80000001>;
				dma-names = "rx";
				nvmem-cells = <0x2c>;
				nvmem-cell-names = "vrefint";
				status = "disabled";
				phandle = <0xb5>;
			};
		};

		sdmmc@48004000 {
			compatible = "arm,pl18x\0arm,primecell";
			arm,primecell-periphid = <0x253180>;
			reg = <0x48004000 0x400>;
			interrupts = <0x00 0x89 0x04>;
			interrupt-names = "cmd_irq";
			clocks = <0x0c 0x78>;
			clock-names = "apb_pclk";
			resets = <0x0c 0x4cd0>;
			cap-sd-highspeed;
			cap-mmc-highspeed;
			max-frequency = <0x7270e00>;
			status = "disabled";
			phandle = <0xb6>;
		};

		usb-otg@49000000 {
			compatible = "st,stm32mp15-hsotg\0snps,dwc2";
			reg = <0x49000000 0x10000>;
			clocks = <0x0c 0xa6>;
			clock-names = "otg";
			resets = <0x0c 0x4cc8>;
			reset-names = "dwc2";
			interrupts-extended = <0x0e 0x2c 0x04>;
			g-rx-fifo-size = <0x200>;
			g-np-tx-fifo-size = <0x20>;
			g-tx-fifo-size = <0x100 0x10 0x10 0x10 0x10 0x10 0x10 0x10>;
			dr_mode = "otg";
			otg-rev = <0x200>;
			usb33d-supply = <0x2d>;
			power-domains = <0x0f>;
			wakeup-source;
			status = "okay";
			phys = <0x2e 0x00>;
			phy-names = "usb2-phy";
			vbus-supply = <0x2f>;
			phandle = <0xb7>;
		};

		hwspinlock@4c000000 {
			compatible = "st,stm32-hwspinlock";
			#hwlock-cells = <0x02>;
			reg = <0x4c000000 0x400>;
			clocks = <0x0c 0x52>;
			clock-names = "hsem";
			phandle = <0x36>;
		};

		mailbox@4c001000 {
			compatible = "st,stm32mp1-ipcc";
			#mbox-cells = <0x01>;
			reg = <0x4c001000 0x400>;
			st,proc-id = <0x00>;
			interrupts-extended = <0x0e 0x3d 0x01 0x07 0x00 0x65 0x04>;
			interrupt-names = "rx\0tx";
			clocks = <0x0c 0x53>;
			wakeup-source;
			power-domains = <0x0f>;
			status = "okay";
			phandle = <0x6f>;
		};

		dcmi@4c006000 {
			compatible = "st,stm32-dcmi";
			reg = <0x4c006000 0x400>;
			interrupts = <0x00 0x4e 0x04>;
			resets = <0x0c 0x4d00>;
			clocks = <0x0c 0x4d>;
			clock-names = "mclk";
			dmas = <0x0d 0x4b 0x400 0xe0000001>;
			dma-names = "tx";
			status = "disabled";
			pinctrl-names = "default\0sleep";
			pinctrl-0 = <0x30>;
			pinctrl-1 = <0x31>;
			phandle = <0xb8>;
		};

		rcc@50000000 {
			compatible = "st,stm32mp1-rcc-secure\0st,stm32mp1-rcc\0syscon";
			reg = <0x50000000 0x1000>;
			#clock-cells = <0x01>;
			#reset-cells = <0x01>;
			interrupts = <0x00 0x05 0x04>;
			clock-names = "hse\0hsi\0csi\0lse\0lsi";
			clocks = <0x01 0x00 0x01 0x01 0x01 0x02 0x01 0x03 0x01 0x04>;
			clocks-boot-on = <0xa7>;
			phandle = <0x0c>;
		};

		pwr@50001000 {
			compatible = "st,stm32mp1,pwr-reg";
			reg = <0x50001000 0x10>;
			st,tzcr = <0x0c 0x00 0x01>;
			vdd-supply = <0x32>;
			vdd_3v3_usbfs-supply = <0x33>;
			phandle = <0xb9>;

			reg11 {
				regulator-name = "reg11";
				regulator-min-microvolt = <0x10c8e0>;
				regulator-max-microvolt = <0x10c8e0>;
				phandle = <0x51>;
			};

			reg18 {
				regulator-name = "reg18";
				regulator-min-microvolt = <0x1b7740>;
				regulator-max-microvolt = <0x1b7740>;
				phandle = <0x52>;
			};

			usb33 {
				regulator-name = "usb33";
				regulator-min-microvolt = <0x325aa0>;
				regulator-max-microvolt = <0x325aa0>;
				phandle = <0x2d>;
			};
		};

		pwr_mcu@50001014 {
			compatible = "st,stm32mp151-pwr-mcu\0syscon";
			reg = <0x50001014 0x04>;
			phandle = <0x66>;
		};

		pwr@50001020 {
			compatible = "st,stm32mp1-pwr";
			reg = <0x50001020 0x100>;
			interrupts = <0x00 0x95 0x04>;
			interrupt-controller;
			#interrupt-cells = <0x03>;
			wakeup-gpios = <0x34 0x00 0x00 0x34 0x02 0x00 0x35 0x0d 0x00 0x1d 0x08 0x00 0x1d 0x0b 0x00 0x35 0x01 0x00>;
			phandle = <0x37>;
		};

		interrupt-controller@5000d000 {
			compatible = "st,stm32mp1-exti\0syscon";
			interrupt-controller;
			#interrupt-cells = <0x02>;
			reg = <0x5000d000 0x400>;
			hwlocks = <0x36 0x01 0x01>;
			phandle = <0x0e>;

			exti-pwr {
				interrupt-controller;
				#interrupt-cells = <0x02>;
				interrupt-parent = <0x37>;
				st,irq-number = <0x06>;
				phandle = <0x5d>;
			};
		};

		syscon@50020000 {
			compatible = "st,stm32mp157-syscfg\0syscon";
			reg = <0x50020000 0x400>;
			clocks = <0x0c 0x33>;
			phandle = <0x0b>;
		};

		timer@50021000 {
			#address-cells = <0x01>;
			#size-cells = <0x00>;
			compatible = "st,stm32-lptimer";
			reg = <0x50021000 0x400>;
			interrupts-extended = <0x0e 0x30 0x04>;
			clocks = <0x0c 0x90>;
			clock-names = "mux";
			power-domains = <0x0f>;
			wakeup-source;
			status = "disabled";
			phandle = <0xba>;

			pwm {
				compatible = "st,stm32-pwm-lp";
				#pwm-cells = <0x03>;
				status = "disabled";
			};

			trigger@1 {
				compatible = "st,stm32-lptimer-trigger";
				reg = <0x01>;
				status = "disabled";
			};

			counter {
				compatible = "st,stm32-lptimer-counter";
				status = "disabled";
			};

			timer {
				compatible = "st,stm32-lptimer-timer";
				status = "disabled";
			};
		};

		timer@50022000 {
			#address-cells = <0x01>;
			#size-cells = <0x00>;
			compatible = "st,stm32-lptimer";
			reg = <0x50022000 0x400>;
			interrupts-extended = <0x0e 0x32 0x04>;
			clocks = <0x0c 0x91>;
			clock-names = "mux";
			power-domains = <0x0f>;
			wakeup-source;
			status = "disabled";
			phandle = <0xbb>;

			pwm {
				compatible = "st,stm32-pwm-lp";
				#pwm-cells = <0x03>;
				status = "disabled";
			};

			trigger@2 {
				compatible = "st,stm32-lptimer-trigger";
				reg = <0x02>;
				status = "disabled";
			};

			timer {
				compatible = "st,stm32-lptimer-timer";
				status = "disabled";
			};
		};

		timer@50023000 {
			compatible = "st,stm32-lptimer";
			reg = <0x50023000 0x400>;
			interrupts-extended = <0x0e 0x34 0x04>;
			clocks = <0x0c 0x92>;
			clock-names = "mux";
			power-domains = <0x0f>;
			wakeup-source;
			status = "disabled";
			phandle = <0xbc>;

			pwm {
				compatible = "st,stm32-pwm-lp";
				#pwm-cells = <0x03>;
				status = "disabled";
			};

			timer {
				compatible = "st,stm32-lptimer-timer";
				status = "disabled";
			};
		};

		timer@50024000 {
			compatible = "st,stm32-lptimer";
			reg = <0x50024000 0x400>;
			interrupts-extended = <0x0e 0x35 0x04>;
			clocks = <0x0c 0x93>;
			clock-names = "mux";
			power-domains = <0x0f>;
			wakeup-source;
			status = "disabled";
			phandle = <0xbd>;

			pwm {
				compatible = "st,stm32-pwm-lp";
				#pwm-cells = <0x03>;
				status = "disabled";
			};

			timer {
				compatible = "st,stm32-lptimer-timer";
				status = "disabled";
			};
		};

		vrefbuf@50025000 {
			compatible = "st,stm32-vrefbuf";
			reg = <0x50025000 0x08>;
			regulator-min-microvolt = <0x2625a0>;
			regulator-max-microvolt = <0x2625a0>;
			clocks = <0x0c 0x34>;
			status = "disabled";
			vdda-supply = <0x32>;
			phandle = <0xbe>;
		};

		sai@50027000 {
			compatible = "st,stm32h7-sai";
			#address-cells = <0x01>;
			#size-cells = <0x01>;
			ranges = <0x00 0x50027000 0x400>;
			reg = <0x50027000 0x04 0x500273f0 0x10>;
			interrupts = <0x00 0x92 0x04>;
			resets = <0x0c 0x4c88>;
			status = "disabled";
			phandle = <0xbf>;

			audio-controller@50027004 {
				#sound-dai-cells = <0x00>;
				compatible = "st,stm32-sai-sub-a";
				reg = <0x04 0x20>;
				clocks = <0x0c 0xa1>;
				clock-names = "sai_ck";
				dmas = <0x0d 0x63 0x400 0x01>;
				status = "disabled";
				phandle = <0xc0>;
			};

			audio-controller@50027024 {
				#sound-dai-cells = <0x00>;
				compatible = "st,stm32-sai-sub-b";
				reg = <0x24 0x20>;
				clocks = <0x0c 0xa1>;
				clock-names = "sai_ck";
				dmas = <0x0d 0x64 0x400 0x01>;
				status = "disabled";
				phandle = <0xc1>;
			};
		};

		thermal@50028000 {
			compatible = "st,stm32-thermal";
			reg = <0x50028000 0x100>;
			interrupts = <0x00 0x93 0x04>;
			clocks = <0x0c 0x35>;
			clock-names = "pclk";
			#thermal-sensor-cells = <0x00>;
			status = "okay";
			phandle = <0x0a>;
		};

		hdp@5002a000 {
			compatible = "st,stm32mp1-hdp";
			reg = <0x5002a000 0x400>;
			clocks = <0x0c 0x37>;
			clock-names = "hdp";
			status = "disabled";
			phandle = <0xc2>;
		};

		hash@54002000 {
			compatible = "st,stm32f756-hash";
			reg = <0x54002000 0x400>;
			interrupts = <0x00 0x50 0x04>;
			clocks = <0x01 0x0c>;
			resets = <0x38 0x07>;
			dmas = <0x27 0x1f 0x02 0x1000a02 0x00 0x00 0x00>;
			dma-names = "in";
			dma-maxburst = <0x02>;
			status = "okay";
			phandle = <0xc3>;
		};

		rng@54003000 {
			compatible = "st,stm32-rng";
			reg = <0x54003000 0x400>;
			clocks = <0x01 0x10>;
			resets = <0x38 0x08>;
			status = "okay";
			phandle = <0xc4>;
		};

		dma-controller@58000000 {
			compatible = "st,stm32h7-mdma";
			reg = <0x58000000 0x1000>;
			interrupts = <0x00 0x7a 0x04>;
			clocks = <0x0c 0x64>;
			resets = <0x38 0x09>;
			#dma-cells = <0x06>;
			dma-channels = <0x20>;
			dma-requests = <0x30>;
			phandle = <0x27>;
		};

		memory-controller@58002000 {
			#address-cells = <0x02>;
			#size-cells = <0x01>;
			compatible = "st,stm32mp1-fmc2-ebi";
			reg = <0x58002000 0x1000>;
			clocks = <0x0c 0x79>;
			resets = <0x0c 0xccc>;
			status = "disabled";
			ranges = <0x00 0x00 0x60000000 0x4000000 0x01 0x00 0x64000000 0x4000000 0x02 0x00 0x68000000 0x4000000 0x03 0x00 0x6c000000 0x4000000 0x04 0x00 0x80000000 0x10000000>;
			pinctrl-names = "default\0sleep";
			pinctrl-0 = <0x39>;
			pinctrl-1 = <0x3a>;
			phandle = <0xc5>;

			nand-controller@4,0 {
				#address-cells = <0x01>;
				#size-cells = <0x00>;
				compatible = "st,stm32mp1-fmc2-nfc";
				reg = <0x04 0x00 0x1000 0x04 0x8010000 0x1000 0x04 0x8020000 0x1000 0x04 0x1000000 0x1000 0x04 0x9010000 0x1000 0x04 0x9020000 0x1000>;
				interrupts = <0x00 0x30 0x04>;
				dmas = <0x27 0x14 0x02 0x12000a02 0x00 0x00 0x00 0x27 0x14 0x02 0x12000a08 0x00 0x00 0x00 0x27 0x15 0x02 0x12000a0a 0x00 0x00 0x00>;
				dma-names = "tx\0rx\0ecc";
				status = "okay";

				nand@0 {
					reg = <0x00>;
					nand-on-flash-bbt;
					nand-ecc-strength = <0x04>;
					nand-ecc-step-size = <0x200>;
					#address-cells = <0x01>;
					#size-cells = <0x01>;
					phandle = <0xc6>;
				};
			};
		};

		spi@58003000 {
			compatible = "st,stm32f469-qspi";
			reg = <0x58003000 0x1000 0x70000000 0x4000000>;
			reg-names = "qspi\0qspi_mm";
			interrupts = <0x00 0x5c 0x04>;
			dmas = <0x27 0x16 0x02 0x10100002 0x00 0x00 0x00 0x27 0x16 0x02 0x10100008 0x00 0x00 0x00>;
			dma-names = "tx\0rx";
			clocks = <0x0c 0x7a>;
			resets = <0x0c 0xcce>;
			#address-cells = <0x01>;
			#size-cells = <0x00>;
			status = "okay";
			pinctrl-names = "default\0sleep";
			pinctrl-0 = <0x3b 0x3c>;
			pinctrl-1 = <0x3d 0x3e>;
			phandle = <0xc7>;

			w25q128@0 {
				compatible = "winbond,w25q128\0jedec,spi-nor\0spi-flash";
				reg = <0x00>;
				spi-rx-bus-width = <0x04>;
				spi-max-frequency = <0x2faf080>;
				m25p,fast-read;
				#address-cells = <0x01>;
				#size-cells = <0x01>;
				phandle = <0xc8>;
			};
		};

		sdmmc@58005000 {
			compatible = "arm,pl18x\0arm,primecell";
			arm,primecell-periphid = <0x253180>;
			reg = <0x58005000 0x1000>;
			interrupts = <0x00 0x31 0x04>;
			interrupt-names = "cmd_irq";
			clocks = <0x0c 0x76>;
			clock-names = "apb_pclk";
			resets = <0x0c 0xcd0>;
			cap-sd-highspeed;
			cap-mmc-highspeed;
			max-frequency = <0x989680>;
			status = "okay";
			pinctrl-names = "default\0opendrain\0sleep";
			pinctrl-0 = <0x3f>;
			pinctrl-1 = <0x40>;
			pinctrl-2 = <0x41>;
			cd-gpios = <0x42 0x03 0x01>;
			st,neg-edge;
			bus-width = <0x04>;
			vmmc-supply = <0x18>;
			phandle = <0xc9>;
		};

		sdmmc@58007000 {
			compatible = "arm,pl18x\0arm,primecell";
			arm,primecell-periphid = <0x253180>;
			reg = <0x58007000 0x1000>;
			interrupts = <0x00 0x7c 0x04>;
			interrupt-names = "cmd_irq";
			clocks = <0x0c 0x77>;
			clock-names = "apb_pclk";
			resets = <0x0c 0xcd1>;
			cap-sd-highspeed;
			cap-mmc-highspeed;
			max-frequency = <0x7270e00>;
			status = "okay";
			pinctrl-names = "default\0opendrain\0sleep";
			pinctrl-0 = <0x43 0x44>;
			pinctrl-1 = <0x45 0x44>;
			pinctrl-2 = <0x46 0x47>;
			non-removable;
			no-sd;
			no-sdio;
			st,neg-edge;
			bus-width = <0x08>;
			vmmc-supply = <0x18>;
			vqmmc-supply = <0x18>;
			mmc-ddr-3_3v;
			phandle = <0xca>;
		};

		crc@58009000 {
			compatible = "st,stm32f7-crc";
			reg = <0x58009000 0x400>;
			clocks = <0x0c 0x6e>;
			status = "okay";
			phandle = <0xcb>;
		};

		ethernet@5800a000 {
			compatible = "st,stm32mp1-dwmac\0snps,dwmac-4.20a";
			reg = <0x5800a000 0x2000>;
			reg-names = "stmmaceth";
			interrupts-extended = <0x07 0x00 0x3d 0x04 0x0e 0x46 0x04>;
			interrupt-names = "macirq\0eth_wake_irq";
			clock-names = "stmmaceth\0mac-clk-tx\0mac-clk-rx\0eth-ck\0syscfg-clk\0ethstp";
			clocks = <0x0c 0x69 0x0c 0x67 0x0c 0x68 0x0c 0x7b 0x0c 0x33 0x0c 0x70>;
			st,syscon = <0x0b 0x04>;
			snps,mixed-burst;
			snps,pbl = <0x02>;
			snps,en-tx-lpi-clockgating;
			snps,axi-config = <0x48>;
			snps,tso;
			power-domains = <0x0f>;
			status = "okay";
			pinctrl-0 = <0x49>;
			pinctrl-1 = <0x4a>;
			pinctrl-names = "default\0sleep";
			phy-mode = "rgmii-id";
			max-speed = <0x3e8>;
			phy-handle = <0x4b>;
			nvmem-cells = <0x4c>;
			nvmem-cell-names = "mac-address";
			st,eth-clk-sel = "true";
			phandle = <0xcc>;

			stmmac-axi-config {
				snps,wr_osr_lmt = <0x07>;
				snps,rd_osr_lmt = <0x07>;
				snps,blen = <0x00 0x00 0x00 0x00 0x10 0x08 0x04>;
				phandle = <0x48>;
			};

			mdio0 {
				#address-cells = <0x01>;
				#size-cells = <0x00>;
				compatible = "snps,dwmac-mdio";

				ethernet-phy@1 {
					compatible = "ethernet-phy-ieee802.3-c22";
					reg = <0x01>;
					interrupt-parent = <0x4d>;
					interrupts = <0x0c 0x02>;
					ti,rx-internal-delay = <0x07>;
					ti,tx-internal-delay = <0x07>;
					ti,fifo-depth = <0x01>;
					ti,min-output-impedance;
					enet-phy-lane-no-swap;
					ti,clk-output-sel = <0xffffffff>;
					phandle = <0x4b>;
				};
			};
		};

		usbh-ohci@5800c000 {
			compatible = "generic-ohci";
			reg = <0x5800c000 0x1000>;
			clocks = <0x0c 0x6f 0x4e>;
			resets = <0x0c 0xcd8>;
			interrupts = <0x00 0x4a 0x04>;
			status = "okay";
			phys = <0x4f>;
			phy-names = "usb";
			phandle = <0x50>;
		};

		usbh-ehci@5800d000 {
			compatible = "generic-ehci";
			reg = <0x5800d000 0x1000>;
			clocks = <0x0c 0x6f>;
			resets = <0x0c 0xcd8>;
			interrupts-extended = <0x0e 0x2b 0x04>;
			companion = <0x50>;
			power-domains = <0x0f>;
			wakeup-source;
			status = "okay";
			phys = <0x4f>;
			phy-names = "usb";
			phandle = <0xcd>;
		};

		display-controller@5a001000 {
			compatible = "st,stm32-ltdc";
			reg = <0x5a001000 0x400>;
			interrupts = <0x00 0x58 0x04 0x00 0x59 0x04>;
			clocks = <0x0c 0xa7>;
			clock-names = "lcd";
			resets = <0x0c 0xc00>;
			status = "disabled";
			phandle = <0xce>;

			port {
				#address-cells = <0x01>;
				#size-cells = <0x00>;
			};
		};

		watchdog@5a002000 {
			compatible = "st,stm32mp1-iwdg";
			reg = <0x5a002000 0x400>;
			clocks = <0x0c 0x3a 0x01 0x04>;
			clock-names = "pclk\0lsi";
			status = "okay";
			timeout-sec = <0x20>;
			phandle = <0xcf>;
		};

		usbphyc@5a006000 {
			#address-cells = <0x01>;
			#size-cells = <0x00>;
			#clock-cells = <0x00>;
			compatible = "st,stm32mp1-usbphyc";
			reg = <0x5a006000 0x1000>;
			clocks = <0x0c 0x7f>;
			resets = <0x0c 0xc10>;
			vdda1v1-supply = <0x51>;
			vdda1v8-supply = <0x52>;
			status = "okay";
			vdd3v3-supply = <0x33>;
			phandle = <0x4e>;

			usb-phy@0 {
				#phy-cells = <0x00>;
				reg = <0x00>;
				phy-supply = <0x33>;
				vbus-supply = <0x53>;
				st,phy-tuning = <0x54>;
				phandle = <0x4f>;
			};

			usb-phy@1 {
				#phy-cells = <0x01>;
				reg = <0x01>;
				phy-supply = <0x33>;
				st,phy-tuning = <0x54>;
				phandle = <0x2e>;
			};
		};

		perf@5a007000 {
			compatible = "st,stm32-ddr-pmu";
			reg = <0x5a007000 0x400>;
			clocks = <0x0c 0xe7>;
			resets = <0x0c 0xc08>;
			status = "disabled";
			phandle = <0xd0>;
		};

		serial@5c000000 {
			compatible = "st,stm32h7-uart";
			reg = <0x5c000000 0x400>;
			interrupts-extended = <0x0e 0x1a 0x04>;
			clocks = <0x01 0x14>;
			resets = <0x38 0x03>;
			wakeup-source;
			power-domains = <0x0f>;
			status = "okay";
			pinctrl-names = "default\0sleep\0idle";
			pinctrl-0 = <0x55 0x56>;
			pinctrl-1 = <0x57 0x58>;
			pinctrl-2 = <0x59 0x5a>;
			uart-has-rtscts;
			phandle = <0xd1>;
		};

		spi@5c001000 {
			#address-cells = <0x01>;
			#size-cells = <0x00>;
			compatible = "st,stm32h7-spi";
			reg = <0x5c001000 0x400>;
			interrupts = <0x00 0x56 0x04>;
			clocks = <0x01 0x13>;
			resets = <0x38 0x00>;
			dmas = <0x27 0x22 0x00 0x40008 0x00 0x00 0x00 0x27 0x23 0x00 0x40002 0x00 0x00 0x00>;
			dma-names = "rx\0tx";
			power-domains = <0x0f>;
			status = "disabled";
			phandle = <0xd2>;
		};

		i2c@5c002000 {
			compatible = "st,stm32mp15-i2c";
			reg = <0x5c002000 0x400>;
			interrupt-names = "event\0error";
			interrupts-extended = <0x0e 0x18 0x04 0x07 0x00 0x60 0x04>;
			clocks = <0x01 0x0d>;
			resets = <0x38 0x01>;
			#address-cells = <0x01>;
			#size-cells = <0x00>;
			power-domains = <0x0f>;
			st,syscfg-fmp = <0x0b 0x04 0x08>;
			wakeup-source;
			i2c-analog-filter;
			status = "okay";
			pinctrl-names = "default\0sleep";
			pinctrl-0 = <0x5b>;
			pinctrl-1 = <0x5c>;
			i2c-scl-rising-time-ns = <0xb9>;
			i2c-scl-falling-time-ns = <0x14>;
			phandle = <0xd3>;

			stpmic@33 {
				compatible = "st,stpmic1";
				reg = <0x33>;
				interrupts-extended = <0x5d 0x37 0x02>;
				interrupt-controller;
				#interrupt-cells = <0x02>;
				status = "okay";
				wakeup-source;
				phandle = <0xd4>;

				regulators {
					compatible = "st,stpmic1-regulators";
					buck1-supply = <0x5e>;
					buck2-supply = <0x5e>;
					buck3-supply = <0x5e>;
					buck4-supply = <0x5e>;
					ldo1-supply = <0x18>;
					ldo2-supply = <0x18>;
					ldo3-supply = <0x5f>;
					ldo4-supply = <0x5e>;
					ldo5-supply = <0x18>;
					ldo6-supply = <0x18>;
					vref_ddr-supply = <0x5e>;
					boost-supply = <0x5e>;
					pwr_sw1-supply = <0x60>;
					pwr_sw2-supply = <0x60>;

					buck1 {
						regulator-name = "vddcore";
						regulator-min-microvolt = <0x124f80>;
						regulator-max-microvolt = <0x149970>;
						regulator-always-on;
						regulator-initial-mode = <0x00>;
						regulator-over-current-protection;
						phandle = <0x04>;
					};

					buck2 {
						regulator-name = "vdd_ddr";
						regulator-min-microvolt = <0x149970>;
						regulator-max-microvolt = <0x149970>;
						regulator-always-on;
						regulator-initial-mode = <0x00>;
						regulator-over-current-protection;
						phandle = <0x5f>;
					};

					buck3 {
						regulator-name = "vdd";
						regulator-min-microvolt = <0x325aa0>;
						regulator-max-microvolt = <0x325aa0>;
						regulator-always-on;
						st,mask-reset;
						regulator-initial-mode = <0x00>;
						regulator-over-current-protection;
						phandle = <0x32>;
					};

					buck4 {
						regulator-name = "v3v3";
						regulator-min-microvolt = <0x325aa0>;
						regulator-max-microvolt = <0x325aa0>;
						regulator-always-on;
						regulator-over-current-protection;
						regulator-initial-mode = <0x00>;
						phandle = <0x18>;
					};

					ldo1 {
						regulator-name = "v1v8_audio";
						regulator-min-microvolt = <0x1b7740>;
						regulator-max-microvolt = <0x1b7740>;
						regulator-always-on;
						interrupts = <0x10 0x00>;
						phandle = <0x19>;
					};

					ldo2 {
						regulator-name = "dd_eth_2v5";
						regulator-min-microvolt = <0x2625a0>;
						regulator-max-microvolt = <0x2625a0>;
						regulator-always-on;
						interrupts = <0x11 0x00>;
						phandle = <0xd5>;
					};

					ldo3 {
						regulator-name = "vtt_ddr";
						regulator-min-microvolt = <0x7a120>;
						regulator-max-microvolt = <0xb71b0>;
						regulator-always-on;
						regulator-over-current-protection;
						phandle = <0xd6>;
					};

					ldo4 {
						regulator-name = "vdd_usb";
						regulator-min-microvolt = <0x325aa0>;
						regulator-max-microvolt = <0x325aa0>;
						interrupts = <0x13 0x00>;
						phandle = <0x33>;
					};

					ldo5 {
						regulator-name = "vdda";
						regulator-min-microvolt = <0x2c4020>;
						regulator-max-microvolt = <0x2c4020>;
						interrupts = <0x14 0x00>;
						regulator-boot-on;
						phandle = <0xd7>;
					};

					ldo6 {
						regulator-name = "vdd_eth_1v0";
						regulator-min-microvolt = <0xf4240>;
						regulator-max-microvolt = <0xf4240>;
						regulator-always-on;
						interrupts = <0x15 0x00>;
						phandle = <0xd8>;
					};

					vref_ddr {
						regulator-name = "vref_ddr";
						regulator-always-on;
						regulator-over-current-protection;
						phandle = <0xd9>;
					};

					boost {
						regulator-name = "bst_out";
						interrupts = <0x0e 0x00>;
						phandle = <0x60>;
					};

					pwr_sw1 {
						regulator-name = "vbus_otg";
						interrupts = <0x0c 0x00>;
						regulator-active-discharge;
						phandle = <0x2f>;
					};

					pwr_sw2 {
						regulator-name = "vbus_sw";
						interrupts = <0x0d 0x00>;
						regulator-active-discharge;
						phandle = <0x53>;
					};
				};

				onkey {
					compatible = "st,stpmic1-onkey";
					interrupts = <0x00 0x00 0x01 0x00>;
					interrupt-names = "onkey-falling\0onkey-rising";
					power-off-time-sec = <0x0a>;
					status = "okay";
				};

				watchdog {
					compatible = "st,stpmic1-wdt";
					status = "disabled";
				};
			};

			eeprom@50 {
				compatible = "microchip,24c32\0atmel,24c32";
				reg = <0x50>;
				status = "okay";
				phandle = <0xda>;
			};

			rtc@52 {
				compatible = "microcrystal,rv3028";
				reg = <0x52>;
				enable-level-switching-mode;
				status = "okay";
				phandle = <0xdb>;
			};
		};

		rtc@5c004000 {
			compatible = "st,stm32mp1-rtc";
			reg = <0x5c004000 0x400>;
			clocks = <0x01 0x12 0x01 0x11>;
			clock-names = "pclk\0rtc_ck";
			interrupts-extended = <0x0e 0x13 0x04>;
			status = "okay";
			phandle = <0xdc>;
		};

		efuse@5c005000 {
			compatible = "st,stm32mp15-bsec";
			reg = <0x5c005000 0x400>;
			clocks = <0x01 0x09>;
			#address-cells = <0x01>;
			#size-cells = <0x01>;
			phandle = <0xdd>;

			part_number_otp@4 {
				reg = <0x04 0x01>;
				phandle = <0x03>;
			};

			calib@52 {
				reg = <0x52 0x02>;
				phandle = <0x2c>;
			};

			calib@5c {
				reg = <0x5c 0x02>;
				phandle = <0xde>;
			};

			calib@5e {
				reg = <0x5e 0x02>;
				phandle = <0xdf>;
			};

			mac@e4 {
				reg = <0xe4 0x06>;
				phandle = <0x4c>;
			};
		};

		i2c@5c009000 {
			compatible = "st,stm32mp15-i2c";
			reg = <0x5c009000 0x400>;
			interrupt-names = "event\0error";
			interrupts-extended = <0x0e 0x36 0x04 0x07 0x00 0x88 0x04>;
			clocks = <0x01 0x0e>;
			resets = <0x38 0x02>;
			#address-cells = <0x01>;
			#size-cells = <0x00>;
			dmas = <0x27 0x26 0x00 0x40008 0x00 0x00 0x00 0x27 0x27 0x00 0x40002 0x00 0x00 0x00>;
			dma-names = "rx\0tx";
			power-domains = <0x0f>;
			st,syscfg-fmp = <0x0b 0x04 0x20>;
			wakeup-source;
			i2c-analog-filter;
			status = "disabled";
			phandle = <0xe0>;
		};

		pin-controller@50002000 {
			#address-cells = <0x01>;
			#size-cells = <0x01>;
			compatible = "st,stm32mp157-pinctrl";
			ranges = <0x00 0x50002000 0xa400>;
			interrupt-parent = <0x0e>;
			st,syscfg = <0x0e 0x60 0xff>;
			hwlocks = <0x36 0x00 0x01>;
			pins-are-numbered;
			st,package = <0x04>;
			phandle = <0x61>;

			gpio@50002000 {
				gpio-controller;
				#gpio-cells = <0x02>;
				interrupt-controller;
				#interrupt-cells = <0x02>;
				reg = <0x00 0x400>;
				clocks = <0x0c 0x54>;
				st,bank-name = "GPIOA";
				status = "okay";
				ngpios = <0x10>;
				gpio-ranges = <0x61 0x00 0x00 0x10>;
				phandle = <0x34>;
			};

			gpio@50003000 {
				gpio-controller;
				#gpio-cells = <0x02>;
				interrupt-controller;
				#interrupt-cells = <0x02>;
				reg = <0x1000 0x400>;
				clocks = <0x0c 0x55>;
				st,bank-name = "GPIOB";
				status = "okay";
				ngpios = <0x10>;
				gpio-ranges = <0x61 0x00 0x10 0x10>;
				phandle = <0xe1>;
			};

			gpio@50004000 {
				gpio-controller;
				#gpio-cells = <0x02>;
				interrupt-controller;
				#interrupt-cells = <0x02>;
				reg = <0x2000 0x400>;
				clocks = <0x0c 0x56>;
				st,bank-name = "GPIOC";
				status = "okay";
				ngpios = <0x10>;
				gpio-ranges = <0x61 0x00 0x20 0x10>;
				phandle = <0x35>;
			};

			gpio@50005000 {
				gpio-controller;
				#gpio-cells = <0x02>;
				interrupt-controller;
				#interrupt-cells = <0x02>;
				reg = <0x3000 0x400>;
				clocks = <0x0c 0x57>;
				st,bank-name = "GPIOD";
				status = "okay";
				ngpios = <0x10>;
				gpio-ranges = <0x61 0x00 0x30 0x10>;
				phandle = <0xe2>;
			};

			gpio@50006000 {
				gpio-controller;
				#gpio-cells = <0x02>;
				interrupt-controller;
				#interrupt-cells = <0x02>;
				reg = <0x4000 0x400>;
				clocks = <0x0c 0x58>;
				st,bank-name = "GPIOE";
				status = "okay";
				ngpios = <0x10>;
				gpio-ranges = <0x61 0x00 0x40 0x10>;
				phandle = <0xe3>;
			};

			gpio@50007000 {
				gpio-controller;
				#gpio-cells = <0x02>;
				interrupt-controller;
				#interrupt-cells = <0x02>;
				reg = <0x5000 0x400>;
				clocks = <0x0c 0x59>;
				st,bank-name = "GPIOF";
				status = "okay";
				ngpios = <0x10>;
				gpio-ranges = <0x61 0x00 0x50 0x10>;
				phandle = <0x42>;
			};

			gpio@50008000 {
				gpio-controller;
				#gpio-cells = <0x02>;
				interrupt-controller;
				#interrupt-cells = <0x02>;
				reg = <0x6000 0x400>;
				clocks = <0x0c 0x5a>;
				st,bank-name = "GPIOG";
				status = "okay";
				ngpios = <0x10>;
				gpio-ranges = <0x61 0x00 0x60 0x10>;
				phandle = <0x4d>;
			};

			gpio@50009000 {
				gpio-controller;
				#gpio-cells = <0x02>;
				interrupt-controller;
				#interrupt-cells = <0x02>;
				reg = <0x7000 0x400>;
				clocks = <0x0c 0x5b>;
				st,bank-name = "GPIOH";
				status = "okay";
				ngpios = <0x10>;
				gpio-ranges = <0x61 0x00 0x70 0x10>;
				phandle = <0xe4>;
			};

			gpio@5000a000 {
				gpio-controller;
				#gpio-cells = <0x02>;
				interrupt-controller;
				#interrupt-cells = <0x02>;
				reg = <0x8000 0x400>;
				clocks = <0x0c 0x5c>;
				st,bank-name = "GPIOI";
				status = "okay";
				ngpios = <0x0c>;
				gpio-ranges = <0x61 0x00 0x80 0x0c>;
				phandle = <0x1d>;
			};

			gpio@5000b000 {
				gpio-controller;
				#gpio-cells = <0x02>;
				interrupt-controller;
				#interrupt-cells = <0x02>;
				reg = <0x9000 0x400>;
				clocks = <0x0c 0x5d>;
				st,bank-name = "GPIOJ";
				status = "disabled";
				phandle = <0xe5>;
			};

			gpio@5000c000 {
				gpio-controller;
				#gpio-cells = <0x02>;
				interrupt-controller;
				#interrupt-cells = <0x02>;
				reg = <0xa000 0x400>;
				clocks = <0x0c 0x5e>;
				st,bank-name = "GPIOK";
				status = "disabled";
				phandle = <0xe6>;
			};

			rgmii-0 {
				phandle = <0x49>;

				pins1 {
					pinmux = <0x640c 0x6d0c 0x6e0c 0x220c 0x420c 0x1b0c 0x20c 0x210c>;
					bias-disable;
					drive-push-pull;
					slew-rate = <0x02>;
				};

				pins2 {
					pinmux = <0x240c 0x250c 0x760c 0x110c 0x10c 0x70c>;
					bias-disable;
				};
			};

			rgmii-sleep-0 {
				phandle = <0x4a>;

				pins1 {
					pinmux = <0x6411 0x6d11 0x6e11 0x2211 0x4211 0x1b11 0x211 0x2111 0x2411 0x2511 0x7611 0x1111 0x111 0x711>;
				};
			};

			fmc-0 {
				phandle = <0x39>;

				pins1 {
					pinmux = <0x340d 0x350d 0x3b0d 0x3c0d 0x3e0d 0x3f0d 0x300d 0x310d 0x470d 0x480d 0x490d 0x4a0d 0x690d>;
					bias-disable;
					drive-push-pull;
					slew-rate = <0x01>;
				};

				pins2 {
					pinmux = <0x360d>;
					bias-pull-up;
				};
			};

			fmc-sleep-0 {
				phandle = <0x3a>;

				pins {
					pinmux = <0x3411 0x3511 0x3b11 0x3c11 0x3e11 0x3f11 0x3011 0x3111 0x4711 0x4811 0x4911 0x4a11 0x3611 0x6911>;
				};
			};

			qspi-bk1-0 {
				phandle = <0x3c>;

				pins1 {
					pinmux = <0x580b 0x590b 0x570a 0x560a>;
					bias-disable;
					drive-push-pull;
					slew-rate = <0x01>;
				};

				pins2 {
					pinmux = <0x160b>;
					bias-pull-up;
					drive-push-pull;
					slew-rate = <0x01>;
				};
			};

			qspi-bk1-sleep-0 {
				phandle = <0x3e>;

				pins {
					pinmux = <0x5811 0x5911 0x5711 0x5611 0x1611>;
				};
			};

			qspi-clk-0 {
				phandle = <0x3b>;

				pins {
					pinmux = <0x5a0a>;
					bias-disable;
					drive-push-pull;
					slew-rate = <0x03>;
				};
			};

			qspi-clk-sleep-0 {
				phandle = <0x3d>;

				pins {
					pinmux = <0x5a11>;
				};
			};

			sdmmc2-b4-0 {
				phandle = <0x43>;

				pins1 {
					pinmux = <0x1e0a 0x1f0a 0x130a 0x140a 0x660b>;
					slew-rate = <0x01>;
					drive-push-pull;
					bias-pull-up;
				};

				pins2 {
					pinmux = <0x430a>;
					slew-rate = <0x02>;
					drive-push-pull;
					bias-pull-up;
				};
			};

			sdmmc2-b4-od-0 {
				phandle = <0x45>;

				pins1 {
					pinmux = <0x1e0a 0x1f0a 0x130a 0x140a>;
					slew-rate = <0x01>;
					drive-push-pull;
					bias-pull-up;
				};

				pins2 {
					pinmux = <0x430a>;
					slew-rate = <0x02>;
					drive-push-pull;
					bias-pull-up;
				};

				pins3 {
					pinmux = <0x660b>;
					slew-rate = <0x01>;
					drive-open-drain;
					bias-pull-up;
				};
			};

			sdmmc2-b4-sleep-0 {
				phandle = <0x46>;

				pins {
					pinmux = <0x1e11 0x1f11 0x1311 0x1411 0x4311 0x6611>;
				};
			};

			sdmmc2-b4-1 {
				phandle = <0xe7>;

				pins1 {
					pinmux = <0x1e0a 0x1f0a 0x130a 0x140a 0x660b>;
					slew-rate = <0x01>;
					drive-push-pull;
					bias-disable;
				};

				pins2 {
					pinmux = <0x430a>;
					slew-rate = <0x02>;
					drive-push-pull;
					bias-disable;
				};
			};

			sdmmc2-b4-od-1 {
				phandle = <0xe8>;

				pins1 {
					pinmux = <0x1e0a 0x1f0a 0x130a 0x140a>;
					slew-rate = <0x01>;
					drive-push-pull;
					bias-disable;
				};

				pins2 {
					pinmux = <0x430a>;
					slew-rate = <0x02>;
					drive-push-pull;
					bias-disable;
				};

				pins3 {
					pinmux = <0x660b>;
					slew-rate = <0x01>;
					drive-open-drain;
					bias-disable;
				};
			};

			sdmmc2-d47-0 {
				phandle = <0x44>;

				pins {
					pinmux = <0x80a 0x90b 0x260b 0x330a>;
					slew-rate = <0x01>;
					drive-push-pull;
					bias-pull-up;
				};
			};

			sdmmc2-d47-sleep-0 {
				phandle = <0x47>;

				pins {
					pinmux = <0x811 0x911 0x2611 0x3311>;
				};
			};

			dac-ch1 {
				phandle = <0xe9>;

				pins {
					pinmux = <0x411>;
				};
			};

			dac-ch2 {
				phandle = <0xea>;

				pins {
					pinmux = <0x511>;
				};
			};

			dcmi-0 {
				phandle = <0x30>;

				pins {
					pinmux = <0x780e 0x170e 0x60e 0x790e 0x270e 0x400e 0x410e 0x7e0e 0x840e 0x450e 0x870e 0x810e 0x770e>;
					bias-disable;
				};
			};

			dcmi-sleep-0 {
				phandle = <0x31>;

				pins {
					pinmux = <0x7811 0x1711 0x611 0x7911 0x2711 0x4011 0x4111 0x7e11 0x8411 0x4511 0x8711 0x8111 0x7711>;
				};
			};

			i2c1-0 {
				phandle = <0x16>;

				pins {
					pinmux = <0x5e06 0x5f06>;
					bias-disable;
					drive-open-drain;
					slew-rate = <0x00>;
				};
			};

			i2c1-1 {
				phandle = <0x17>;

				pins {
					pinmux = <0x5e11 0x5f11>;
				};
			};

			ltdc-a-0 {
				phandle = <0xeb>;

				pins {
					pinmux = <0x670f 0x8a0f 0x890f 0x4d0f 0x2a0f 0x100a 0x7a0f 0x7b0f 0x7c0f 0x4f0f 0x7d0f 0x4b0f 0x7f0f 0x740a 0x8b0a 0x820f 0x6a0f 0x6b0f 0x4c0f 0x850f 0x180f 0x380f>;
					bias-disable;
					drive-push-pull;
					slew-rate = <0x01>;
				};
			};

			ltdc-a-1 {
				phandle = <0xec>;

				pins {
					pinmux = <0x6711 0x8a11 0x8911 0x4d11 0x2a11 0x1011 0x7a11 0x7b11 0x7c11 0x4f11 0x7d11 0x4b11 0x7f11 0x7411 0x8b11 0x8211 0x6a11 0x6b11 0x4c11 0x8511 0x1811 0x3811>;
				};
			};

			pwm5-0 {
				phandle = <0xed>;

				pins {
					pinmux = <0x8003>;
					bias-pull-down;
					drive-push-pull;
					slew-rate = <0x00>;
				};
			};

			pwm5-sleep-0 {
				phandle = <0xee>;

				pins {
					pinmux = <0x8011>;
				};
			};

			sai2a-2 {
				phandle = <0x21>;

				pins {
					pinmux = <0x860b>;
					bias-disable;
				};
			};

			sai2a-3 {
				phandle = <0x23>;

				pins {
					pinmux = <0x8611>;
				};
			};

			sai2b-0 {
				phandle = <0x22>;

				pins1 {
					pinmux = <0x720b 0x2009 0x730b>;
					slew-rate = <0x00>;
					drive-push-pull;
					bias-disable;
				};

				pins2 {
					pinmux = <0x5b0b>;
					bias-disable;
				};
			};

			sai2b-1 {
				phandle = <0x24>;

				pins {
					pinmux = <0x5b11 0x7211 0x2011 0x7311>;
				};
			};

			sai2b-2 {
				phandle = <0xef>;

				pins {
					pinmux = <0x5b0b>;
					bias-disable;
				};
			};

			sai2b-3 {
				phandle = <0xf0>;

				pins {
					pinmux = <0x5b11>;
				};
			};

			sdmmc1-b4-0 {
				phandle = <0x3f>;

				pins1 {
					pinmux = <0x280d 0x290d 0x4609 0x2b0d 0x320d>;
					slew-rate = <0x01>;
					drive-push-pull;
					bias-disable;
				};

				pins2 {
					pinmux = <0x2c0d>;
					slew-rate = <0x02>;
					drive-push-pull;
					bias-disable;
				};
			};

			sdmmc1-b4-od-0 {
				phandle = <0x40>;

				pins1 {
					pinmux = <0x280d 0x290d 0x4609 0x2b0d>;
					slew-rate = <0x01>;
					drive-push-pull;
					bias-disable;
				};

				pins2 {
					pinmux = <0x2c0d>;
					slew-rate = <0x02>;
					drive-push-pull;
					bias-disable;
				};

				pins3 {
					pinmux = <0x320d>;
					slew-rate = <0x01>;
					drive-open-drain;
					bias-disable;
				};
			};

			sdmmc1-b4-sleep-0 {
				phandle = <0x41>;

				pins {
					pinmux = <0x2811 0x2911 0x4611 0x2b11 0x2c11 0x3211>;
				};
			};

			sdmmc3-b4-0 {
				phandle = <0xf1>;

				pins1 {
					pinmux = <0x500a 0x540a 0x550a 0x370b 0x510a>;
					slew-rate = <0x01>;
					drive-push-pull;
					bias-pull-up;
				};

				pins2 {
					pinmux = <0x6f0b>;
					slew-rate = <0x02>;
					drive-push-pull;
					bias-pull-up;
				};
			};

			sdmmc3-b4-od-0 {
				phandle = <0xf2>;

				pins1 {
					pinmux = <0x500a 0x540a 0x550a 0x370b>;
					slew-rate = <0x01>;
					drive-push-pull;
					bias-pull-up;
				};

				pins2 {
					pinmux = <0x6f0b>;
					slew-rate = <0x02>;
					drive-push-pull;
					bias-pull-up;
				};

				pins3 {
					pinmux = <0x510a>;
					slew-rate = <0x01>;
					drive-open-drain;
					bias-pull-up;
				};
			};

			sdmmc3-b4-sleep-0 {
				phandle = <0xf3>;

				pins {
					pinmux = <0x5011 0x5411 0x5511 0x3711 0x6f11 0x5111>;
				};
			};

			uart4-0 {
				phandle = <0x13>;

				pins1 {
					pinmux = <0x1909>;
					bias-disable;
					drive-push-pull;
					slew-rate = <0x00>;
				};

				pins2 {
					pinmux = <0x1209>;
					bias-disable;
				};
			};

			uart4-idle-0 {
				phandle = <0x15>;

				pins1 {
					pinmux = <0x1911>;
				};

				pins2 {
					pinmux = <0x1209>;
					bias-disable;
				};
			};

			uart4-sleep-0 {
				phandle = <0x14>;

				pins {
					pinmux = <0x1911 0x1211>;
				};
			};

			usart1-1 {
				phandle = <0x56>;

				pins1 {
					pinmux = <0xc08>;
					bias-disable;
					drive-push-pull;
					slew-rate = <0x00>;
				};

				pins2 {
					pinmux = <0xb08>;
					bias-disable;
				};
			};

			usart1-idle-1 {
				phandle = <0x5a>;

				pins1 {
					pinmux = <0xc11 0xb08>;
				};
			};

			usart1-sleep-1 {
				phandle = <0x58>;

				pins {
					pinmux = <0xc11 0xb11>;
				};
			};

			usbotg_hs-0 {
				phandle = <0xf7>;

				pins {
					pinmux = <0xa11>;
				};
			};
		};

		pin-controller-z@54004000 {
			#address-cells = <0x01>;
			#size-cells = <0x01>;
			compatible = "st,stm32mp157-z-pinctrl";
			ranges = <0x00 0x54004000 0x400>;
			pins-are-numbered;
			interrupt-parent = <0x0e>;
			st,syscfg = <0x0e 0x60 0xff>;
			hwlocks = <0x36 0x00 0x01>;
			st,package = <0x04>;
			phandle = <0x62>;

			gpio@54004000 {
				gpio-controller;
				#gpio-cells = <0x02>;
				interrupt-controller;
				#interrupt-cells = <0x02>;
				reg = <0x00 0x400>;
				clocks = <0x01 0x0b>;
				st,bank-name = "GPIOZ";
				st,bank-ioport = <0x0b>;
				status = "okay";
				ngpios = <0x08>;
				gpio-ranges = <0x62 0x00 0x190 0x08>;
				phandle = <0x20>;
			};

			i2c4-0 {
				phandle = <0x5b>;

				pins {
					pinmux = <0x19407 0x19507>;
					bias-disable;
					drive-open-drain;
					slew-rate = <0x00>;
				};
			};

			i2c4-1 {
				phandle = <0x5c>;

				pins {
					pinmux = <0x19411 0x19511>;
				};
			};

			usart1-0 {
				phandle = <0x55>;

				pins1 {
					pinmux = <0x19708>;
					bias-disable;
					drive-push-pull;
					slew-rate = <0x00>;
				};

				pins2 {
					pinmux = <0x19608>;
					bias-disable;
				};
			};

			usart1-idle-0 {
				phandle = <0x59>;

				pins1 {
					pinmux = <0x19711>;
				};

				pins2 {
					pinmux = <0x19608>;
					bias-disable;
				};
			};

			usart1-sleep-0 {
				phandle = <0x57>;

				pins {
					pinmux = <0x19711 0x19611>;
				};
			};

			spi1-0 {
				phandle = <0x1e>;

				pins1 {
					pinmux = <0x19006 0x19206>;
					bias-disable;
					drive-push-pull;
					slew-rate = <0x01>;
				};

				pins2 {
					pinmux = <0x19106>;
					bias-disable;
				};
			};

			spi1-sleep-0 {
				phandle = <0x1f>;

				pins {
					pinmux = <0x19011 0x19111 0x19211>;
				};
			};
		};

		tamp@5c00a000 {
			compatible = "simple-bus\0syscon\0simple-mfd";
			reg = <0x5c00a000 0x400>;
			phandle = <0x67>;

			reboot-mode {
				compatible = "syscon-reboot-mode";
				offset = <0x150>;
				mask = <0xff>;
				mode-normal = <0x00>;
				mode-fastboot = <0x01>;
				mode-recovery = <0x02>;
				mode-stm32cubeprogrammer = <0x03>;
				mode-ums_mmc0 = <0x10>;
				mode-ums_mmc1 = <0x11>;
				mode-ums_mmc2 = <0x12>;
			};
		};

		can@4400e000 {
			compatible = "bosch,m_can";
			reg = <0x4400e000 0x400 0x44011000 0x1400>;
			reg-names = "m_can\0message_ram";
			interrupts = <0x00 0x13 0x04 0x00 0x15 0x04>;
			interrupt-names = "int0\0int1";
			clocks = <0x01 0x00 0x0c 0x9d>;
			clock-names = "hclk\0cclk";
			bosch,mram-cfg = <0x00 0x00 0x00 0x20 0x00 0x00 0x02 0x02>;
			status = "disabled";
			phandle = <0xf8>;
		};

		can@4400f000 {
			compatible = "bosch,m_can";
			reg = <0x4400f000 0x400 0x44011000 0x2800>;
			reg-names = "m_can\0message_ram";
			interrupts = <0x00 0x14 0x04 0x00 0x16 0x04>;
			interrupt-names = "int0\0int1";
			clocks = <0x01 0x00 0x0c 0x9d>;
			clock-names = "hclk\0cclk";
			bosch,mram-cfg = <0x1400 0x00 0x00 0x20 0x00 0x00 0x02 0x02>;
			status = "disabled";
			phandle = <0xf9>;
		};

		gpu@59000000 {
			compatible = "vivante,gc";
			reg = <0x59000000 0x800>;
			interrupts = <0x00 0x6d 0x04>;
			clocks = <0x0c 0x65 0x0c 0x7e>;
			clock-names = "bus\0core";
			resets = <0x0c 0xcc5>;
			status = "okay";
			contiguous-area = <0x65>;
			phandle = <0xfa>;
		};

		dsi@5a000000 {
			compatible = "st,stm32-dsi";
			reg = <0x5a000000 0x800>;
			phy-dsi-supply = <0x52>;
			clocks = <0x0c 0xa3 0x01 0x00 0x0c 0xa4>;
			clock-names = "pclk\0ref\0px_clk";
			resets = <0x0c 0xc04>;
			reset-names = "apb";
			#address-cells = <0x01>;
			#size-cells = <0x00>;
			status = "disabled";
			phandle = <0xfb>;

			ports {
				#address-cells = <0x01>;
				#size-cells = <0x00>;
			};
		};

		cryp@54001000 {
			compatible = "st,stm32mp1-cryp";
			reg = <0x54001000 0x400>;
			interrupts = <0x00 0x4f 0x04>;
			clocks = <0x01 0x0a>;
			resets = <0x38 0x06>;
			status = "okay";
			phandle = <0xfc>;
		};
	};

	ahb {
		compatible = "st,mlahb\0simple-bus";
		#address-cells = <0x01>;
		#size-cells = <0x01>;
		ranges;
		dma-ranges = <0x00 0x38000000 0x10000 0x10000000 0x10000000 0x60000 0x30000000 0x30000000 0x60000>;
		phandle = <0xfd>;

		m4@10000000 {
			compatible = "st,stm32mp1-m4";
			reg = <0x10000000 0x40000 0x30000000 0x40000 0x38000000 0x10000>;
			resets = <0x38 0x0a 0x38 0x0b>;
			reset-names = "mcu_rst\0hold_boot";
			st,syscfg-pdds = <0x66 0x00 0x01>;
			st,syscfg-rsc-tbl = <0x67 0x144 0xffffffff>;
			st,syscfg-m4-state = <0x67 0x148 0xffffffff>;
			status = "okay";
			memory-region = <0x68 0x69 0x6a 0x6b 0x6c 0x6d 0x6e>;
			mboxes = <0x6f 0x00 0x6f 0x01 0x6f 0x02>;
			mbox-names = "vq0\0vq1\0shutdown";
			interrupt-parent = <0x0e>;
			interrupts = <0x44 0x01>;
			wakeup-source;
			phandle = <0xfe>;

			m4_system_resources {
				compatible = "rproc-srm-core";
				status = "disabled";
				#address-cells = <0x01>;
				#size-cells = <0x00>;

				timer@40000000 {
					compatible = "rproc-srm-dev";
					reg = <0x40000000 0x400>;
					clocks = <0x0c 0xc5>;
					clock-names = "int";
					status = "disabled";
					phandle = <0xff>;
				};

				timer@40001000 {
					compatible = "rproc-srm-dev";
					reg = <0x40001000 0x400>;
					clocks = <0x0c 0xc6>;
					clock-names = "int";
					status = "disabled";
					phandle = <0x100>;
				};

				timer@40002000 {
					compatible = "rproc-srm-dev";
					reg = <0x40002000 0x400>;
					clocks = <0x0c 0xc7>;
					clock-names = "int";
					status = "disabled";
					phandle = <0x101>;
				};

				timer@40003000 {
					compatible = "rproc-srm-dev";
					reg = <0x40003000 0x400>;
					clocks = <0x0c 0xc8>;
					clock-names = "int";
					status = "disabled";
					phandle = <0x102>;
				};

				timer@40004000 {
					compatible = "rproc-srm-dev";
					reg = <0x40004000 0x400>;
					clocks = <0x0c 0xc9>;
					clock-names = "int";
					status = "disabled";
					phandle = <0x103>;
				};

				timer@40005000 {
					compatible = "rproc-srm-dev";
					reg = <0x40005000 0x400>;
					clocks = <0x0c 0xca>;
					clock-names = "int";
					status = "disabled";
					phandle = <0x104>;
				};

				timer@40006000 {
					compatible = "rproc-srm-dev";
					reg = <0x40006000 0x400>;
					clocks = <0x0c 0xcb>;
					clock-names = "int";
					status = "disabled";
					phandle = <0x105>;
				};

				timer@40007000 {
					compatible = "rproc-srm-dev";
					reg = <0x40007000 0x400>;
					clocks = <0x0c 0xcc>;
					clock-names = "int";
					status = "disabled";
					phandle = <0x106>;
				};

				timer@40008000 {
					compatible = "rproc-srm-dev";
					reg = <0x40008000 0x400>;
					clocks = <0x0c 0xcd>;
					clock-names = "int";
					status = "disabled";
					phandle = <0x107>;
				};

				timer@40009000 {
					compatible = "rproc-srm-dev";
					reg = <0x40009000 0x400>;
					clocks = <0x0c 0x8f>;
					clock-names = "mux";
					status = "disabled";
					phandle = <0x108>;
				};

				spi@4000b000 {
					compatible = "rproc-srm-dev";
					reg = <0x4000b000 0x400>;
					clocks = <0x0c 0x83>;
					status = "disabled";
					phandle = <0x109>;
				};

				audio-controller@4000b000 {
					compatible = "rproc-srm-dev";
					reg = <0x4000b000 0x400>;
					status = "disabled";
					phandle = <0x10a>;
				};

				spi@4000c000 {
					compatible = "rproc-srm-dev";
					reg = <0x4000c000 0x400>;
					clocks = <0x0c 0x84>;
					status = "disabled";
					phandle = <0x10b>;
				};

				audio-controller@4000c000 {
					compatible = "rproc-srm-dev";
					reg = <0x4000c000 0x400>;
					status = "disabled";
					phandle = <0x10c>;
				};

				audio-controller@4000d000 {
					compatible = "rproc-srm-dev";
					reg = <0x4000d000 0x400>;
					clocks = <0x0c 0x81>;
					clock-names = "kclk";
					status = "disabled";
					phandle = <0x10d>;
				};

				serial@4000e000 {
					compatible = "rproc-srm-dev";
					reg = <0x4000e000 0x400>;
					interrupt-parent = <0x0e>;
					interrupts = <0x1b 0x01>;
					clocks = <0x0c 0x95>;
					status = "disabled";
					phandle = <0x10e>;
				};

				serial@4000f000 {
					compatible = "rproc-srm-dev";
					reg = <0x4000f000 0x400>;
					interrupt-parent = <0x0e>;
					interrupts = <0x1c 0x01>;
					clocks = <0x0c 0x96>;
					status = "disabled";
					phandle = <0x10f>;
				};

				serial@40010000 {
					compatible = "rproc-srm-dev";
					reg = <0x40010000 0x400>;
					interrupt-parent = <0x0e>;
					interrupts = <0x1e 0x01>;
					clocks = <0x0c 0x97>;
					status = "disabled";
					phandle = <0x110>;
				};

				serial@40011000 {
					compatible = "rproc-srm-dev";
					reg = <0x40011000 0x400>;
					interrupt-parent = <0x0e>;
					interrupts = <0x1f 0x01>;
					clocks = <0x0c 0x98>;
					status = "disabled";
					phandle = <0x111>;
				};

				i2c@40012000 {
					compatible = "rproc-srm-dev";
					reg = <0x40012000 0x400>;
					interrupt-parent = <0x0e>;
					interrupts = <0x15 0x01>;
					clocks = <0x0c 0x89>;
					status = "disabled";
					phandle = <0x112>;
				};

				i2c@40013000 {
					compatible = "rproc-srm-dev";
					reg = <0x40013000 0x400>;
					interrupt-parent = <0x0e>;
					interrupts = <0x16 0x01>;
					clocks = <0x0c 0x8a>;
					status = "disabled";
					phandle = <0x113>;
				};

				i2c@40014000 {
					compatible = "rproc-srm-dev";
					reg = <0x40014000 0x400>;
					interrupt-parent = <0x0e>;
					interrupts = <0x17 0x01>;
					clocks = <0x0c 0x8b>;
					status = "disabled";
					phandle = <0x114>;
				};

				i2c@40015000 {
					compatible = "rproc-srm-dev";
					reg = <0x40015000 0x400>;
					interrupt-parent = <0x0e>;
					interrupts = <0x19 0x01>;
					clocks = <0x0c 0x8d>;
					status = "disabled";
					phandle = <0x115>;
				};

				cec@40016000 {
					compatible = "rproc-srm-dev";
					reg = <0x40016000 0x400>;
					interrupt-parent = <0x0e>;
					interrupts = <0x45 0x01>;
					clocks = <0x0c 0x88 0x0c 0x1d>;
					clock-names = "cec\0hdmi-cec";
					status = "disabled";
					phandle = <0x116>;
				};

				dac@40017000 {
					compatible = "rproc-srm-dev";
					reg = <0x40017000 0x400>;
					clocks = <0x0c 0x1e>;
					clock-names = "pclk";
					status = "disabled";
					phandle = <0x117>;
				};

				serial@40018000 {
					compatible = "rproc-srm-dev";
					reg = <0x40018000 0x400>;
					interrupt-parent = <0x0e>;
					interrupts = <0x20 0x01>;
					clocks = <0x0c 0x9a>;
					status = "disabled";
					phandle = <0x118>;
				};

				serial@40019000 {
					compatible = "rproc-srm-dev";
					reg = <0x40019000 0x400>;
					interrupt-parent = <0x0e>;
					interrupts = <0x21 0x01>;
					clocks = <0x0c 0x9b>;
					status = "disabled";
					phandle = <0x119>;
				};

				timer@44000000 {
					compatible = "rproc-srm-dev";
					reg = <0x44000000 0x400>;
					clocks = <0x0c 0xce>;
					clock-names = "int";
					status = "disabled";
					phandle = <0x11a>;
				};

				timer@44001000 {
					compatible = "rproc-srm-dev";
					reg = <0x44001000 0x400>;
					clocks = <0x0c 0xcf>;
					clock-names = "int";
					status = "disabled";
					phandle = <0x11b>;
				};

				serial@44003000 {
					compatible = "rproc-srm-dev";
					reg = <0x44003000 0x400>;
					interrupt-parent = <0x0e>;
					interrupts = <0x1d 0x01>;
					clocks = <0x0c 0x99>;
					status = "disabled";
					phandle = <0x11c>;
				};

				spi@44004000 {
					compatible = "rproc-srm-dev";
					reg = <0x44004000 0x400>;
					clocks = <0x0c 0x82>;
					status = "disabled";
					phandle = <0x11d>;
				};

				audio-controller@44004000 {
					compatible = "rproc-srm-dev";
					reg = <0x44004000 0x400>;
					status = "disabled";
					phandle = <0x11e>;
				};

				spi@44005000 {
					compatible = "rproc-srm-dev";
					reg = <0x44005000 0x400>;
					clocks = <0x0c 0x85>;
					status = "disabled";
					phandle = <0x11f>;
				};

				timer@44006000 {
					compatible = "rproc-srm-dev";
					reg = <0x44006000 0x400>;
					clocks = <0x0c 0xd0>;
					clock-names = "int";
					status = "disabled";
					phandle = <0x120>;
				};

				timer@44007000 {
					compatible = "rproc-srm-dev";
					reg = <0x44007000 0x400>;
					clocks = <0x0c 0xd1>;
					clock-names = "int";
					status = "disabled";
					phandle = <0x121>;
				};

				timer@44008000 {
					compatible = "rproc-srm-dev";
					reg = <0x44008000 0x400>;
					clocks = <0x0c 0xd2>;
					clock-names = "int";
					status = "disabled";
					phandle = <0x122>;
				};

				spi@44009000 {
					compatible = "rproc-srm-dev";
					reg = <0x44009000 0x400>;
					clocks = <0x0c 0x86>;
					status = "disabled";
					phandle = <0x123>;
				};

				sai@4400a000 {
					compatible = "rproc-srm-dev";
					reg = <0x4400a000 0x04>;
					clocks = <0x0c 0x9e>;
					clock-names = "sai_ck";
					status = "disabled";
					phandle = <0x124>;
				};

				sai@4400b000 {
					compatible = "rproc-srm-dev";
					reg = <0x4400b000 0x04>;
					clocks = <0x0c 0x9f>;
					clock-names = "sai_ck";
					status = "disabled";
					phandle = <0x125>;
				};

				sai@4400c000 {
					compatible = "rproc-srm-dev";
					reg = <0x4400c000 0x04>;
					clocks = <0x0c 0xa0>;
					clock-names = "sai_ck";
					status = "disabled";
					phandle = <0x126>;
				};

				dfsdm@4400d000 {
					compatible = "rproc-srm-dev";
					reg = <0x4400d000 0x800>;
					clocks = <0x0c 0x9c 0x0c 0xa5>;
					clock-names = "dfsdm\0audio";
					status = "disabled";
					phandle = <0x127>;
				};

				can@4400e000 {
					compatible = "rproc-srm-dev";
					reg = <0x4400e000 0x400 0x44011000 0x2800>;
					clocks = <0x01 0x00 0x0c 0x9d>;
					clock-names = "hclk\0cclk";
					status = "disabled";
					phandle = <0x128>;
				};

				can@4400f000 {
					compatible = "rproc-srm-dev";
					reg = <0x4400f000 0x400 0x44011000 0x2800>;
					clocks = <0x01 0x00 0x0c 0x9d>;
					clock-names = "hclk\0cclk";
					status = "disabled";
					phandle = <0x129>;
				};

				dma@48000000 {
					compatible = "rproc-srm-dev";
					reg = <0x48000000 0x400>;
					clocks = <0x0c 0x47>;
					status = "disabled";
					phandle = <0x12a>;
				};

				dma@48001000 {
					compatible = "rproc-srm-dev";
					reg = <0x48001000 0x400>;
					clocks = <0x0c 0x48>;
					status = "disabled";
					phandle = <0x12b>;
				};

				dma-router@48002000 {
					compatible = "rproc-srm-dev";
					reg = <0x48002000 0x1c>;
					clocks = <0x0c 0x49>;
					status = "disabled";
					phandle = <0x12c>;
				};

				adc@48003000 {
					compatible = "rproc-srm-dev";
					reg = <0x48003000 0x400>;
					clocks = <0x0c 0x4a 0x0c 0xa2>;
					clock-names = "bus\0adc";
					status = "disabled";
					phandle = <0x12d>;
				};

				sdmmc@48004000 {
					compatible = "rproc-srm-dev";
					reg = <0x48004000 0x400 0x48005000 0x400>;
					clocks = <0x0c 0x78>;
					status = "disabled";
					phandle = <0x12e>;
				};

				usb-otg@49000000 {
					compatible = "rproc-srm-dev";
					reg = <0x49000000 0x10000>;
					clocks = <0x0c 0xa6>;
					clock-names = "otg";
					status = "disabled";
					phandle = <0x12f>;
				};

				hash@4c002000 {
					compatible = "rproc-srm-dev";
					reg = <0x4c002000 0x400>;
					clocks = <0x0c 0x4f>;
					status = "disabled";
					phandle = <0x130>;
				};

				rng@4c003000 {
					compatible = "rproc-srm-dev";
					reg = <0x4c003000 0x400>;
					clocks = <0x0c 0x7d>;
					status = "disabled";
					phandle = <0x131>;
				};

				crc@4c004000 {
					compatible = "rproc-srm-dev";
					reg = <0x4c004000 0x400>;
					clocks = <0x0c 0x51>;
					status = "disabled";
					phandle = <0x132>;
				};

				cryp@4c005000 {
					compatible = "rproc-srm-dev";
					reg = <0x4c005000 0x400>;
					clocks = <0x0c 0x4e>;
					status = "disabled";
					phandle = <0x133>;
				};

				dcmi@4c006000 {
					compatible = "rproc-srm-dev";
					reg = <0x4c006000 0x400>;
					clocks = <0x0c 0x4d>;
					clock-names = "mclk";
					status = "disabled";
					phandle = <0x134>;
				};

				timer@50021000 {
					compatible = "rproc-srm-dev";
					reg = <0x50021000 0x400>;
					clocks = <0x0c 0x90>;
					clock-names = "mux";
					status = "disabled";
					phandle = <0x135>;
				};

				timer@50022000 {
					compatible = "rproc-srm-dev";
					reg = <0x50022000 0x400>;
					clocks = <0x0c 0x91>;
					clock-names = "mux";
					status = "disabled";
					phandle = <0x136>;
				};

				timer@50023000 {
					compatible = "rproc-srm-dev";
					reg = <0x50023000 0x400>;
					clocks = <0x0c 0x92>;
					clock-names = "mux";
					status = "disabled";
					phandle = <0x137>;
				};

				timer@50024000 {
					compatible = "rproc-srm-dev";
					reg = <0x50024000 0x400>;
					clocks = <0x0c 0x93>;
					clock-names = "mux";
					status = "disabled";
					phandle = <0x138>;
				};

				sai@50027000 {
					compatible = "rproc-srm-dev";
					reg = <0x50027000 0x04>;
					clocks = <0x0c 0xa1>;
					clock-names = "sai_ck";
					status = "disabled";
					phandle = <0x139>;
				};

				memory-controller@58002000 {
					compatible = "rproc-srm-dev";
					reg = <0x5800200 0x1000>;
					clocks = <0x0c 0x79>;
					status = "disabled";
					phandle = <0x13a>;
				};

				qspi@58003000 {
					compatible = "rproc-srm-dev";
					reg = <0x58003000 0x1000 0x70000000 0x10000000>;
					clocks = <0x0c 0x7a>;
					status = "disabled";
					phandle = <0x13b>;
				};

				ethernet@5800a000 {
					compatible = "rproc-srm-dev";
					reg = <0x5800a000 0x2000>;
					clock-names = "stmmaceth\0mac-clk-tx\0mac-clk-rx\0ethstp\0syscfg-clk";
					clocks = <0x0c 0x69 0x0c 0x67 0x0c 0x68 0x0c 0x70 0x0c 0x33>;
					status = "disabled";
					phandle = <0x13c>;
				};
			};
		};
	};

	memory@c0000000 {
		reg = <0xc0000000 0x20000000>;
	};

	aliases {
		mmc0 = "/soc/sdmmc@58005000";
		mmc1 = "/soc/sdmmc@58007000";
		mmc2 = "/soc/sdmmc@48004000";
		ethernet0 = "/soc/ethernet@5800a000";
		rtc0 = "/soc/i2c@5c002000/rtc@52";
		rtc1 = "/soc/rtc@5c004000";
		serial0 = "/soc/serial@40010000";
		serial1 = "/soc/serial@4000f000";
		serial2 = "/soc/serial@5c000000";
	};

	reserved-memory {
		#address-cells = <0x01>;
		#size-cells = <0x01>;
		ranges;

		retram@0x38000000 {
			compatible = "shared-dma-pool";
			reg = <0x38000000 0x10000>;
			no-map;
			phandle = <0x68>;
		};

		mcuram@0x30000000 {
			compatible = "shared-dma-pool";
			reg = <0x30000000 0x40000>;
			no-map;
			phandle = <0x69>;
		};

		mcuram2@0x10000000 {
			compatible = "shared-dma-pool";
			reg = <0x10000000 0x40000>;
			no-map;
			phandle = <0x6a>;
		};

		mcu_rsc_table@10048000 {
			compatible = "shared-dma-pool";
			reg = <0x10048000 0x8000>;
			no-map;
			phandle = <0x6e>;
		};

		vdev0vring0@10040000 {
			compatible = "shared-dma-pool";
			reg = <0x10040000 0x2000>;
			no-map;
			phandle = <0x6b>;
		};

		vdev0vring1@10042000 {
			compatible = "shared-dma-pool";
			reg = <0x10042000 0x2000>;
			no-map;
			phandle = <0x6c>;
		};

		vdev0buffer@10044000 {
			compatible = "shared-dma-pool";
			reg = <0x10044000 0x4000>;
			no-map;
			phandle = <0x6d>;
		};

		gpu@f8000000 {
			reg = <0xf8000000 0x8000000>;
			no-map;
			phandle = <0x65>;
		};
	};

	vin {
		compatible = "regulator-fixed";
		regulator-name = "vin";
		regulator-min-microvolt = <0x4c4b40>;
		regulator-max-microvolt = <0x4c4b40>;
		regulator-always-on;
		phandle = <0x5e>;
	};

	chosen {
		stdout-path = "serial0:115200n8";
	};

	clocks {

		clk-ext-camera {
			#clock-cells = <0x00>;
			compatible = "fixed-clock";
			clock-frequency = <0x19bfcc0>;
			status = "disabled";
			phandle = <0x13d>;
		};
	};

	sound {
		compatible = "audio-graph-card";
		label = "STM32MP1-PHYCORE";
		routing = "Playback\0MCLK\0Capture\0MCLK";
		dais = <0x70 0x71>;
		status = "okay";
	};

	gpio-keys {
		compatible = "gpio-keys";
		status = "okay";
		phandle = <0x13e>;

		home {
			label = "Home";
			gpios = <0x34 0x0d 0x01>;
			linux,code = <0x66>;
		};

		enter {
			label = "Enter";
			gpios = <0x34 0x0e 0x01>;
			linux,code = <0x1c>;
		};
	};

	usb-phy-tuning {
		st,hs-dc-level = <0x02>;
		st,fs-rftime-tuning;
		st,hs-rftime-reduction;
		st,hs-current-trim = <0x0f>;
		st,hs-impedance-trim = <0x01>;
		st,squelch-level = <0x03>;
		st,hs-rx-offset = <0x02>;
		st,no-lsfs-sc;
		phandle = <0x54>;
	};

	regulator-mcan {
		compatible = "regulator-fixed";
		regulator-name = "mcan-reg";
		regulator-min-microvolt = <0x325aa0>;
		regulator-max-microvolt = <0x325aa0>;
		gpio = <0x4d 0x01 0x00>;
		regulator-always-on;
		status = "disabled";
		phandle = <0x13f>;
	};

	regulator-cam {
		compatible = "regulator-fixed";
		regulator-name = "vcc_cam";
		regulator-min-microvolt = <0x2ab980>;
		regulator-max-microvolt = <0x2ab980>;
		status = "disabled";
		phandle = <0x140>;
	};

	__symbols__ {
		cpu0 = "/cpus/cpu@0";
		cpu1 = "/cpus/cpu@1";
		cpu0_opp_table = "/cpu0-opp-table";
		scmi_sram = "/sram@2ffff000";
		scmi0_shm = "/sram@2ffff000/scmi_shm@0";
		scmi1_shm = "/sram@2ffff000/scmi_shm@200";
		scmi0 = "/firmware/scmi0";
		scmi0_clk = "/firmware/scmi0/protocol@14";
		scmi0_reset = "/firmware/scmi0/protocol@16";
		scmi1 = "/firmware/scmi1";
		scmi1_clk = "/firmware/scmi1/protocol@14";
		intc = "/interrupt-controller@a0021000";
		cpu_thermal = "/thermal-zones/cpu-thermal";
		booster = "/regulator-booster";
		pd_core_ret = "/pm_domain/core-ret-power-domain@1";
		pd_core = "/pm_domain/core-ret-power-domain@1/core-power-domain@2";
		sram = "/soc/sram@10000000";
		dma_pool = "/soc/sram@10000000/dma_pool@0";
		timers2 = "/soc/timer@40000000";
		timers3 = "/soc/timer@40001000";
		timers4 = "/soc/timer@40002000";
		timers5 = "/soc/timer@40003000";
		timers6 = "/soc/timer@40004000";
		timers7 = "/soc/timer@40005000";
		timers12 = "/soc/timer@40006000";
		timers13 = "/soc/timer@40007000";
		timers14 = "/soc/timer@40008000";
		lptimer1 = "/soc/timer@40009000";
		spi2 = "/soc/spi@4000b000";
		i2s2 = "/soc/audio-controller@4000b000";
		spi3 = "/soc/spi@4000c000";
		i2s3 = "/soc/audio-controller@4000c000";
		spdifrx = "/soc/audio-controller@4000d000";
		usart2 = "/soc/serial@4000e000";
		usart3 = "/soc/serial@4000f000";
		uart4 = "/soc/serial@40010000";
		uart5 = "/soc/serial@40011000";
		i2c1 = "/soc/i2c@40012000";
		codec = "/soc/i2c@40012000/tlv320@18";
		tlv320_port = "/soc/i2c@40012000/tlv320@18/port";
		tlv320_tx_endpoint = "/soc/i2c@40012000/tlv320@18/port/endpoint@0";
		tlv320_rx_endpoint = "/soc/i2c@40012000/tlv320@18/port/endpoint@1";
		stmpe_touch = "/soc/i2c@40012000/stmpe811@44";
		leds = "/soc/i2c@40012000/pca9533@62";
		i2c2 = "/soc/i2c@40013000";
		i2c3 = "/soc/i2c@40014000";
		i2c5 = "/soc/i2c@40015000";
		cec = "/soc/cec@40016000";
		dac = "/soc/dac@40017000";
		dac1 = "/soc/dac@40017000/dac@1";
		dac2 = "/soc/dac@40017000/dac@2";
		uart7 = "/soc/serial@40018000";
		uart8 = "/soc/serial@40019000";
		timers1 = "/soc/timer@44000000";
		timers8 = "/soc/timer@44001000";
		usart6 = "/soc/serial@44003000";
		spi1 = "/soc/spi@44004000";
		i2s1 = "/soc/audio-controller@44004000";
		spi4 = "/soc/spi@44005000";
		timers15 = "/soc/timer@44006000";
		timers16 = "/soc/timer@44007000";
		timers17 = "/soc/timer@44008000";
		spi5 = "/soc/spi@44009000";
		sai1 = "/soc/sai@4400a000";
		sai1a = "/soc/sai@4400a000/audio-controller@4400a004";
		sai1b = "/soc/sai@4400a000/audio-controller@4400a024";
		sai2 = "/soc/sai@4400b000";
		sai2a = "/soc/sai@4400b000/audio-controller@4400b004";
		sai2a_port = "/soc/sai@4400b000/audio-controller@4400b004/port";
		sai2a_endpoint = "/soc/sai@4400b000/audio-controller@4400b004/port/endpoint";
		sai2b = "/soc/sai@4400b000/audio-controller@4400b024";
		sai2b_port = "/soc/sai@4400b000/audio-controller@4400b024/port";
		sai2b_endpoint = "/soc/sai@4400b000/audio-controller@4400b024/port/endpoint";
		sai3 = "/soc/sai@4400c000";
		sai3a = "/soc/sai@4400c000/audio-controller@4400c004";
		sai3b = "/soc/sai@4400c000/audio-controller@4400c024";
		dfsdm = "/soc/dfsdm@4400d000";
		dfsdm0 = "/soc/dfsdm@4400d000/filter@0";
		dfsdm1 = "/soc/dfsdm@4400d000/filter@1";
		dfsdm2 = "/soc/dfsdm@4400d000/filter@2";
		dfsdm3 = "/soc/dfsdm@4400d000/filter@3";
		dfsdm4 = "/soc/dfsdm@4400d000/filter@4";
		dfsdm5 = "/soc/dfsdm@4400d000/filter@5";
		dma1 = "/soc/dma-controller@48000000";
		dma2 = "/soc/dma-controller@48001000";
		dmamux1 = "/soc/dma-router@48002000";
		adc = "/soc/adc@48003000";
		adc1 = "/soc/adc@48003000/adc@0";
		adc2 = "/soc/adc@48003000/adc@100";
		sdmmc3 = "/soc/sdmmc@48004000";
		usbotg_hs = "/soc/usb-otg@49000000";
		hsem = "/soc/hwspinlock@4c000000";
		ipcc = "/soc/mailbox@4c001000";
		dcmi = "/soc/dcmi@4c006000";
		rcc = "/soc/rcc@50000000";
		pwr_regulators = "/soc/pwr@50001000";
		reg11 = "/soc/pwr@50001000/reg11";
		reg18 = "/soc/pwr@50001000/reg18";
		usb33 = "/soc/pwr@50001000/usb33";
		pwr_mcu = "/soc/pwr_mcu@50001014";
		pwr_irq = "/soc/pwr@50001020";
		exti = "/soc/interrupt-controller@5000d000";
		exti_pwr = "/soc/interrupt-controller@5000d000/exti-pwr";
		syscfg = "/soc/syscon@50020000";
		lptimer2 = "/soc/timer@50021000";
		lptimer3 = "/soc/timer@50022000";
		lptimer4 = "/soc/timer@50023000";
		lptimer5 = "/soc/timer@50024000";
		vrefbuf = "/soc/vrefbuf@50025000";
		sai4 = "/soc/sai@50027000";
		sai4a = "/soc/sai@50027000/audio-controller@50027004";
		sai4b = "/soc/sai@50027000/audio-controller@50027024";
		dts = "/soc/thermal@50028000";
		hdp = "/soc/hdp@5002a000";
		hash1 = "/soc/hash@54002000";
		rng1 = "/soc/rng@54003000";
		mdma1 = "/soc/dma-controller@58000000";
		fmc = "/soc/memory-controller@58002000";
		nand = "/soc/memory-controller@58002000/nand-controller@4,0/nand@0";
		qspi = "/soc/spi@58003000";
		flash0 = "/soc/spi@58003000/w25q128@0";
		sdmmc1 = "/soc/sdmmc@58005000";
		sdmmc2 = "/soc/sdmmc@58007000";
		crc1 = "/soc/crc@58009000";
		ethernet0 = "/soc/ethernet@5800a000";
		stmmac_axi_config_0 = "/soc/ethernet@5800a000/stmmac-axi-config";
		phy0 = "/soc/ethernet@5800a000/mdio0/ethernet-phy@1";
		usbh_ohci = "/soc/usbh-ohci@5800c000";
		usbh_ehci = "/soc/usbh-ehci@5800d000";
		ltdc = "/soc/display-controller@5a001000";
		iwdg2 = "/soc/watchdog@5a002000";
		usbphyc = "/soc/usbphyc@5a006000";
		usbphyc_port0 = "/soc/usbphyc@5a006000/usb-phy@0";
		usbphyc_port1 = "/soc/usbphyc@5a006000/usb-phy@1";
		ddrperfm = "/soc/perf@5a007000";
		usart1 = "/soc/serial@5c000000";
		spi6 = "/soc/spi@5c001000";
		i2c4 = "/soc/i2c@5c002000";
		pmic = "/soc/i2c@5c002000/stpmic@33";
		vddcore = "/soc/i2c@5c002000/stpmic@33/regulators/buck1";
		vdd_ddr = "/soc/i2c@5c002000/stpmic@33/regulators/buck2";
		vdd = "/soc/i2c@5c002000/stpmic@33/regulators/buck3";
		v3v3 = "/soc/i2c@5c002000/stpmic@33/regulators/buck4";
		v1v8_audio = "/soc/i2c@5c002000/stpmic@33/regulators/ldo1";
		vdd_eth_2v5 = "/soc/i2c@5c002000/stpmic@33/regulators/ldo2";
		vtt_ddr = "/soc/i2c@5c002000/stpmic@33/regulators/ldo3";
		vdd_usb = "/soc/i2c@5c002000/stpmic@33/regulators/ldo4";
		vdda = "/soc/i2c@5c002000/stpmic@33/regulators/ldo5";
		vdd_eth_1v0 = "/soc/i2c@5c002000/stpmic@33/regulators/ldo6";
		vref_ddr = "/soc/i2c@5c002000/stpmic@33/regulators/vref_ddr";
		bst_out = "/soc/i2c@5c002000/stpmic@33/regulators/boost";
		vbus_otg = "/soc/i2c@5c002000/stpmic@33/regulators/pwr_sw1";
		vbus_sw = "/soc/i2c@5c002000/stpmic@33/regulators/pwr_sw2";
		i2c4_eeprom = "/soc/i2c@5c002000/eeprom@50";
		i2c4_rtc = "/soc/i2c@5c002000/rtc@52";
		rtc = "/soc/rtc@5c004000";
		bsec = "/soc/efuse@5c005000";
		part_number_otp = "/soc/efuse@5c005000/part_number_otp@4";
		vrefint = "/soc/efuse@5c005000/calib@52";
		ts_cal1 = "/soc/efuse@5c005000/calib@5c";
		ts_cal2 = "/soc/efuse@5c005000/calib@5e";
		ethernet_mac_address = "/soc/efuse@5c005000/mac@e4";
		i2c6 = "/soc/i2c@5c009000";
		pinctrl = "/soc/pin-controller@50002000";
		gpioa = "/soc/pin-controller@50002000/gpio@50002000";
		gpiob = "/soc/pin-controller@50002000/gpio@50003000";
		gpioc = "/soc/pin-controller@50002000/gpio@50004000";
		gpiod = "/soc/pin-controller@50002000/gpio@50005000";
		gpioe = "/soc/pin-controller@50002000/gpio@50006000";
		gpiof = "/soc/pin-controller@50002000/gpio@50007000";
		gpiog = "/soc/pin-controller@50002000/gpio@50008000";
		gpioh = "/soc/pin-controller@50002000/gpio@50009000";
		gpioi = "/soc/pin-controller@50002000/gpio@5000a000";
		gpioj = "/soc/pin-controller@50002000/gpio@5000b000";
		gpiok = "/soc/pin-controller@50002000/gpio@5000c000";
		ethernet0_rgmii_pins_a = "/soc/pin-controller@50002000/rgmii-0";
		ethernet0_rgmii_pins_sleep_a = "/soc/pin-controller@50002000/rgmii-sleep-0";
		fmc_pins_a = "/soc/pin-controller@50002000/fmc-0";
		fmc_sleep_pins_a = "/soc/pin-controller@50002000/fmc-sleep-0";
		qspi_bk1_pins_a = "/soc/pin-controller@50002000/qspi-bk1-0";
		qspi_bk1_sleep_pins_a = "/soc/pin-controller@50002000/qspi-bk1-sleep-0";
		qspi_clk_pins_a = "/soc/pin-controller@50002000/qspi-clk-0";
		qspi_clk_sleep_pins_a = "/soc/pin-controller@50002000/qspi-clk-sleep-0";
		sdmmc2_b4_pins_a = "/soc/pin-controller@50002000/sdmmc2-b4-0";
		sdmmc2_b4_od_pins_a = "/soc/pin-controller@50002000/sdmmc2-b4-od-0";
		sdmmc2_b4_sleep_pins_a = "/soc/pin-controller@50002000/sdmmc2-b4-sleep-0";
		sdmmc2_b4_pins_b = "/soc/pin-controller@50002000/sdmmc2-b4-1";
		sdmmc2_b4_od_pins_b = "/soc/pin-controller@50002000/sdmmc2-b4-od-1";
		sdmmc2_d47_pins_a = "/soc/pin-controller@50002000/sdmmc2-d47-0";
		sdmmc2_d47_sleep_pins_a = "/soc/pin-controller@50002000/sdmmc2-d47-sleep-0";
		dac_ch1_pins_a = "/soc/pin-controller@50002000/dac-ch1";
		dac_ch2_pins_a = "/soc/pin-controller@50002000/dac-ch2";
		dcmi_pins_a = "/soc/pin-controller@50002000/dcmi-0";
		dcmi_sleep_pins_a = "/soc/pin-controller@50002000/dcmi-sleep-0";
		i2c1_pins_a = "/soc/pin-controller@50002000/i2c1-0";
		i2c1_pins_sleep_a = "/soc/pin-controller@50002000/i2c1-1";
		ltdc_pins_a = "/soc/pin-controller@50002000/ltdc-a-0";
		ltdc_pins_sleep_a = "/soc/pin-controller@50002000/ltdc-a-1";
		pwm5_pins_a = "/soc/pin-controller@50002000/pwm5-0";
		pwm5_sleep_pins_a = "/soc/pin-controller@50002000/pwm5-sleep-0";
		sai2a_pins_b = "/soc/pin-controller@50002000/sai2a-2";
		sai2a_sleep_pins_b = "/soc/pin-controller@50002000/sai2a-3";
		sai2b_pins_a = "/soc/pin-controller@50002000/sai2b-0";
		sai2b_sleep_pins_a = "/soc/pin-controller@50002000/sai2b-1";
		sai2b_pins_b = "/soc/pin-controller@50002000/sai2b-2";
		sai2b_sleep_pins_b = "/soc/pin-controller@50002000/sai2b-3";
		sdmmc1_b4_pins_a = "/soc/pin-controller@50002000/sdmmc1-b4-0";
		sdmmc1_b4_od_pins_a = "/soc/pin-controller@50002000/sdmmc1-b4-od-0";
		sdmmc1_b4_sleep_pins_a = "/soc/pin-controller@50002000/sdmmc1-b4-sleep-0";
		sdmmc3_b4_pins_a = "/soc/pin-controller@50002000/sdmmc3-b4-0";
		sdmmc3_b4_od_pins_a = "/soc/pin-controller@50002000/sdmmc3-b4-od-0";
		sdmmc3_b4_sleep_pins_a = "/soc/pin-controller@50002000/sdmmc3-b4-sleep-0";
		uart4_pins_a = "/soc/pin-controller@50002000/uart4-0";
		uart4_idle_pins_a = "/soc/pin-controller@50002000/uart4-idle-0";
		uart4_sleep_pins_a = "/soc/pin-controller@50002000/uart4-sleep-0";
		usart1_pins_b = "/soc/pin-controller@50002000/usart1-1";
		usart1_idle_pins_b = "/soc/pin-controller@50002000/usart1-idle-1";
		usart1_sleep_pins_b = "/soc/pin-controller@50002000/usart1-sleep-1";
		usbotg_hs_pins_a = "/soc/pin-controller@50002000/usbotg_hs-0";
		pinctrl_z = "/soc/pin-controller-z@54004000";
		gpioz = "/soc/pin-controller-z@54004000/gpio@54004000";
		i2c4_pins_a = "/soc/pin-controller-z@54004000/i2c4-0";
		i2c4_pins_sleep_a = "/soc/pin-controller-z@54004000/i2c4-1";
		usart1_pins_a = "/soc/pin-controller-z@54004000/usart1-0";
		usart1_idle_pins_a = "/soc/pin-controller-z@54004000/usart1-idle-0";
		usart1_sleep_pins_a = "/soc/pin-controller-z@54004000/usart1-sleep-0";
		spi1_pins_a = "/soc/pin-controller-z@54004000/spi1-0";
		spi1_sleep_pins_a = "/soc/pin-controller-z@54004000/spi1-sleep-0";
		tamp = "/soc/tamp@5c00a000";
		m_can1 = "/soc/can@4400e000";
		m_can2 = "/soc/can@4400f000";
		gpu = "/soc/gpu@59000000";
		dsi = "/soc/dsi@5a000000";
		cryp1 = "/soc/cryp@54001000";
		mlahb = "/ahb";
		m4_rproc = "/ahb/m4@10000000";
		m4_timers2 = "/ahb/m4@10000000/m4_system_resources/timer@40000000";
		m4_timers3 = "/ahb/m4@10000000/m4_system_resources/timer@40001000";
		m4_timers4 = "/ahb/m4@10000000/m4_system_resources/timer@40002000";
		m4_timers5 = "/ahb/m4@10000000/m4_system_resources/timer@40003000";
		m4_timers6 = "/ahb/m4@10000000/m4_system_resources/timer@40004000";
		m4_timers7 = "/ahb/m4@10000000/m4_system_resources/timer@40005000";
		m4_timers12 = "/ahb/m4@10000000/m4_system_resources/timer@40006000";
		m4_timers13 = "/ahb/m4@10000000/m4_system_resources/timer@40007000";
		m4_timers14 = "/ahb/m4@10000000/m4_system_resources/timer@40008000";
		m4_lptimer1 = "/ahb/m4@10000000/m4_system_resources/timer@40009000";
		m4_spi2 = "/ahb/m4@10000000/m4_system_resources/spi@4000b000";
		m4_i2s2 = "/ahb/m4@10000000/m4_system_resources/audio-controller@4000b000";
		m4_spi3 = "/ahb/m4@10000000/m4_system_resources/spi@4000c000";
		m4_i2s3 = "/ahb/m4@10000000/m4_system_resources/audio-controller@4000c000";
		m4_spdifrx = "/ahb/m4@10000000/m4_system_resources/audio-controller@4000d000";
		m4_usart2 = "/ahb/m4@10000000/m4_system_resources/serial@4000e000";
		m4_usart3 = "/ahb/m4@10000000/m4_system_resources/serial@4000f000";
		m4_uart4 = "/ahb/m4@10000000/m4_system_resources/serial@40010000";
		m4_uart5 = "/ahb/m4@10000000/m4_system_resources/serial@40011000";
		m4_i2c1 = "/ahb/m4@10000000/m4_system_resources/i2c@40012000";
		m4_i2c2 = "/ahb/m4@10000000/m4_system_resources/i2c@40013000";
		m4_i2c3 = "/ahb/m4@10000000/m4_system_resources/i2c@40014000";
		m4_i2c5 = "/ahb/m4@10000000/m4_system_resources/i2c@40015000";
		m4_cec = "/ahb/m4@10000000/m4_system_resources/cec@40016000";
		m4_dac = "/ahb/m4@10000000/m4_system_resources/dac@40017000";
		m4_uart7 = "/ahb/m4@10000000/m4_system_resources/serial@40018000";
		m4_uart8 = "/ahb/m4@10000000/m4_system_resources/serial@40019000";
		m4_timers1 = "/ahb/m4@10000000/m4_system_resources/timer@44000000";
		m4_timers8 = "/ahb/m4@10000000/m4_system_resources/timer@44001000";
		m4_usart6 = "/ahb/m4@10000000/m4_system_resources/serial@44003000";
		m4_spi1 = "/ahb/m4@10000000/m4_system_resources/spi@44004000";
		m4_i2s1 = "/ahb/m4@10000000/m4_system_resources/audio-controller@44004000";
		m4_spi4 = "/ahb/m4@10000000/m4_system_resources/spi@44005000";
		m4_timers15 = "/ahb/m4@10000000/m4_system_resources/timer@44006000";
		m4_timers16 = "/ahb/m4@10000000/m4_system_resources/timer@44007000";
		m4_timers17 = "/ahb/m4@10000000/m4_system_resources/timer@44008000";
		m4_spi5 = "/ahb/m4@10000000/m4_system_resources/spi@44009000";
		m4_sai1 = "/ahb/m4@10000000/m4_system_resources/sai@4400a000";
		m4_sai2 = "/ahb/m4@10000000/m4_system_resources/sai@4400b000";
		m4_sai3 = "/ahb/m4@10000000/m4_system_resources/sai@4400c000";
		m4_dfsdm = "/ahb/m4@10000000/m4_system_resources/dfsdm@4400d000";
		m4_m_can1 = "/ahb/m4@10000000/m4_system_resources/can@4400e000";
		m4_m_can2 = "/ahb/m4@10000000/m4_system_resources/can@4400f000";
		m4_dma1 = "/ahb/m4@10000000/m4_system_resources/dma@48000000";
		m4_dma2 = "/ahb/m4@10000000/m4_system_resources/dma@48001000";
		m4_dmamux1 = "/ahb/m4@10000000/m4_system_resources/dma-router@48002000";
		m4_adc = "/ahb/m4@10000000/m4_system_resources/adc@48003000";
		m4_sdmmc3 = "/ahb/m4@10000000/m4_system_resources/sdmmc@48004000";
		m4_usbotg_hs = "/ahb/m4@10000000/m4_system_resources/usb-otg@49000000";
		m4_hash2 = "/ahb/m4@10000000/m4_system_resources/hash@4c002000";
		m4_rng2 = "/ahb/m4@10000000/m4_system_resources/rng@4c003000";
		m4_crc2 = "/ahb/m4@10000000/m4_system_resources/crc@4c004000";
		m4_cryp2 = "/ahb/m4@10000000/m4_system_resources/cryp@4c005000";
		m4_dcmi = "/ahb/m4@10000000/m4_system_resources/dcmi@4c006000";
		m4_lptimer2 = "/ahb/m4@10000000/m4_system_resources/timer@50021000";
		m4_lptimer3 = "/ahb/m4@10000000/m4_system_resources/timer@50022000";
		m4_lptimer4 = "/ahb/m4@10000000/m4_system_resources/timer@50023000";
		m4_lptimer5 = "/ahb/m4@10000000/m4_system_resources/timer@50024000";
		m4_sai4 = "/ahb/m4@10000000/m4_system_resources/sai@50027000";
		m4_fmc = "/ahb/m4@10000000/m4_system_resources/memory-controller@58002000";
		m4_qspi = "/ahb/m4@10000000/m4_system_resources/qspi@58003000";
		m4_ethernet0 = "/ahb/m4@10000000/m4_system_resources/ethernet@5800a000";
		retram = "/reserved-memory/retram@0x38000000";
		mcuram = "/reserved-memory/mcuram@0x30000000";
		mcuram2 = "/reserved-memory/mcuram2@0x10000000";
		mcu_rsc_table = "/reserved-memory/mcu_rsc_table@10048000";
		vdev0vring0 = "/reserved-memory/vdev0vring0@10040000";
		vdev0vring1 = "/reserved-memory/vdev0vring1@10042000";
		vdev0buffer = "/reserved-memory/vdev0buffer@10044000";
		gpu_reserved = "/reserved-memory/gpu@f8000000";
		vin = "/vin";
		clk_ext_camera = "/clocks/clk-ext-camera";
		gpio_keys = "/gpio-keys";
		usb_phy_tuning = "/usb-phy-tuning";
		reg_m_can = "/regulator-mcan";
		reg_vcc_cam = "/regulator-cam";
	};
};
